VERSION ""

NS_ :

BS_:

BU_:

BO_ 2284109824 BMU_Heartbeat: 7 Vector__XXX
 SG_ BMU_Heartbeat_State : 0|8@1+ (1,0) [0|0] "" Vector__XXX
 SG_ BMU_Heartbeat_Flags : 8|32@1+ (1,0) [0|0] "" Vector__XXX

BO_ 2290139136 VCU_Heartbeat_SHDN: 6 Vector__XXX
 SG_ VCU_Heartbeat_SHDN_State : 0|8@1+ (1,0) [0|0] "" Vector__XXX
 SG_ VCU_Heartbeat_SHDN_Flags : 8|32@1+ (1,0) [0|0] "" Vector__XXX

BO_ 2290139137 VCU_Heartbeat_CTRL: 6 Vector__XXX
 SG_ VCU_Heartbeat_CTRL_State : 0|8@1+ (1,0) [0|0] "" Vector__XXX
 SG_ VCU_Heartbeat_CTRL_Flags : 8|32@1+ (1,0) [0|0] "" Vector__XXX

BO_ 2290139138 VCU_Heartbeat_DASH: 6 Vector__XXX
 SG_ VCU_Heartbeat_DASH_State : 0|8@1+ (1,0) [0|0] "" Vector__XXX
 SG_ VCU_Heartbeat_DASH_Flags : 8|32@1+ (1,0) [0|0] "" Vector__XXX

BO_ 2290139139 VCU_Heartbeat_EBS: 6 Vector__XXX
 SG_ VCU_Heartbeat_EBS_State : 0|8@1+ (1,0) [0|0] "" Vector__XXX
 SG_ VCU_Heartbeat_EBS_Flags : 8|32@1+ (1,0) [0|0] "" Vector__XXX

BO_ 2290139140 VCU_Heartbeat_ASSI: 6 Vector__XXX
 SG_ VCU_Heartbeat_ASSI_State : 0|8@1+ (1,0) [0|0] "" Vector__XXX
 SG_ VCU_Heartbeat_ASSI_Flags : 8|32@1+ (1,0) [0|0] "" Vector__XXX

BO_ 2290139141 VCU_Heartbeat_EBS_ADC: 6 Vector__XXX
 SG_ VCU_Heartbeat_EBS_ADC_State : 0|8@1+ (1,0) [0|0] "" Vector__XXX
 SG_ VCU_Heartbeat_EBS_ADC_Flags : 8|32@1+ (1,0) [0|0] "" Vector__XXX

BO_ 2290139142 VCU_Heartbeat_ACCU: 6 Vector__XXX
 SG_ VCU_Heartbeat_ACCU_State : 0|8@1+ (1,0) [0|0] "" Vector__XXX
 SG_ VCU_Heartbeat_ACCU_Flags : 8|32@1+ (1,0) [0|0] "" Vector__XXX

BO_ 2290139143 VCU_Heartbeat_COOL_L: 6 Vector__XXX
 SG_ VCU_Heartbeat_COOL_L_State : 0|8@1+ (1,0) [0|0] "" Vector__XXX
 SG_ VCU_Heartbeat_COOL_L_Flags : 8|32@1+ (1,0) [0|0] "" Vector__XXX

BO_ 2290139144 VCU_Heartbeat_COOL_R: 6 Vector__XXX
 SG_ VCU_Heartbeat_COOL_R_State : 0|8@1+ (1,0) [0|0] "" Vector__XXX
 SG_ VCU_Heartbeat_COOL_R_Flags : 8|32@1+ (1,0) [0|0] "" Vector__XXX

BO_ 2290139145 VCU_Heartbeat_SENSOR: 6 Vector__XXX
 SG_ VCU_Heartbeat_SENSOR_State : 0|8@1+ (1,0) [0|0] "" Vector__XXX
 SG_ VCU_Heartbeat_SENSOR_Flags : 8|32@1+ (1,0) [0|0] "" Vector__XXX

BO_ 2424340480 VCU_ShutdownStatus: 3 Vector__XXX
 SG_ VCU_ShutdownLines : 0|16@1+ (1,0) [0|0] "" Vector__XXX
 SG_ VCU_ShutdownStatus : 16|8@1+ (1,0) [0|1] "" Vector__XXX

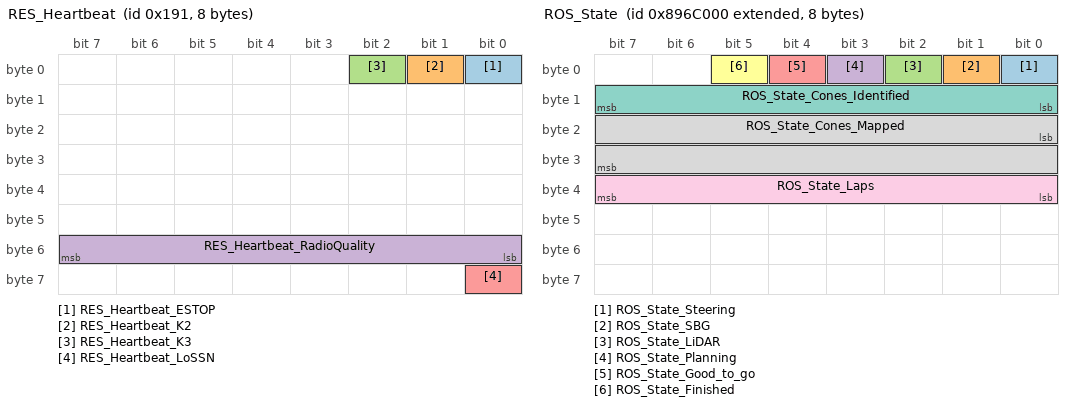
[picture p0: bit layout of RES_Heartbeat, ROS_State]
BO_ 401 RES_Heartbeat: 8 Vector__XXX
 SG_ RES_Heartbeat_ESTOP : 0|1@1- (1,0) [0|1] "" Vector__XXX
 SG_ RES_Heartbeat_K2 : 1|1@1- (1,0) [0|1] "" Vector__XXX
 SG_ RES_Heartbeat_K3 : 2|1@1- (1,0) [0|1] "" Vector__XXX
 SG_ RES_Heartbeat_RadioQuality : 48|8@1+ (1,0) [0|255] "" Vector__XXX
 SG_ RES_Heartbeat_LoSSN : 56|1@1- (1,0) [0|1] "" Vector__XXX

BO_ 2286731264 EBS_CTRL_Heartbeat: 8 Vector___XXX
 SG_ EBS_CTRL_Heartbeat_State : 0|8@1+ (1, 0) [0|0] "" Vector__XXX
 SG_ EBS_CTRL_Heartbeat_Flags : 8|32@1+ (1, 0) [0|0] "" Vector__XXX

BO_ 2286206977 MCISO_Heartbeat_Right: 8 Vector__XXX
 SG_ MCISO_Heartbeat_Right_State : 0|8@1+ (1,0) [0|0] "" Vector__XXX
 SG_ MCISO_Heartbeat_Right_Flags : 8|8@1+ (1,0) [0|0] "" Vector__XXX

BO_ 2286206976 MCISO_Heartbeat_Left: 8 Vector__XXX
 SG_ MCISO_Heartbeat_Left_State : 0|8@1+ (1,0) [0|0] "" Vector__XXX
 SG_ MCISO_Heartbeat_Left_Flags : 8|8@1+ (1,0) [0|0] "" Vector__XXX

BO_ 2290401280 SW_Heartbeat: 8 Vector__XXX
 SG_ SW_Heartbeat_State : 0|8@1+ (1,0) [0|0] "" Vector__XXX
 SG_ SW_Heartbeat_MissionID : 8|8@1+ (1,0) [0|0] "" Vector__XXX
 SG_ SW_Heartbeat_Flags : 16|16@1+ (1,0) [0|0] "" Vector__XXX

BO_ 2425274368 DVL_Heartbeat: 8 Vector__XXX
 SG_ DVL_Heartbeat_State : 0|8@1+ (1,0) [0|0] "" Vector__XXX
 SG_ DVL_Heartbeat_Flags : 8|32@1+ (1,0) [0|0] "" Vector__XXX

BO_ 2291318784 AV_State: 8 Vector__XXX
 SG_ AV_State_Mode : 0|8@1+ (1,0) [0|0] "" Vector__XXX
 SG_ AV_State_Mission : 8|8@1+ (1,0) [0|0] "" Vector__XXX
 SG_ AV_State_Status : 16|8@1+ (1,0) [0|0] "" Vector__XXX

BO_ 2291580928 ROS_State: 8 Vector__XXX
 SG_ ROS_State_Steering : 0|1@1+ (1,0) [0|0] "" Vector__XXX
 SG_ ROS_State_SBG : 1|1@1+ (1,0) [0|0] "" Vector__XXX
 SG_ ROS_State_LiDAR : 2|1@1+ (1,0) [0|0] "" Vector__XXX
 SG_ ROS_State_Planning : 3|1@1+ (1,0) [0|0] "" Vector__XXX
 SG_ ROS_State_Good_to_go : 4|1@1+ (1,0) [0|0] "" Vector__XXX
 SG_ ROS_State_Finished : 5|1@1+ (1,0) [0|0] "" Vector__XXX

 SG_ ROS_State_Cones_Identified : 8|8@1+ (1,0) [0|0] "" Vector__XXX
 SG_ ROS_State_Cones_Mapped : 16|16@1+ (1,0) [0|0] "" Vector__XXX
 SG_ ROS_State_Laps : 32|8@1+ (1,0) [0|0] "" Vector__XXX

BO_ 2424340665 VCU_Suspension_Rot_Front: 8 Vector__XXX
 SG_ VCU_Suspension_Rot_FL_ADC : 7|16@0+ (1,0) [0|0] "" Vector__XXX
 SG_ VCU_Suspension_Rot_FR_ADC : 23|16@0+ (1,0) [0|0] "" Vector__XXX
 SG_ VCU_Suspension_Rot_FL : 39|16@0- (0.001,0) [0|0] "" Vector__XXX
 SG_ VCU_Suspension_Rot_FR : 55|16@0- (0.001,0) [0|0] "" Vector__XXX

BO_ 2424340662 VCU_Suspension_Rot_Rear: 8 Vector__XXX
 SG_ VCU_Suspension_Rot_RL_ADC : 7|16@0+ (1,0) [0|0] "" Vector__XXX
 SG_ VCU_Suspension_Rot_RR_ADC : 23|16@0+ (1,0) [0|0] "" Vector__XXX
 SG_ VCU_Suspension_Rot_RL : 39|16@0- (0.001,0) [0|0] "" Vector__XXX
 SG_ VCU_Suspension_Rot_RR : 55|16@0- (0.001,0) [0|0] "" Vector__XXX

BO_ 2424340648 VCU_Temp_Gearbox_Right: 8 Vector__XXX
 SG_ VCU_Gearbox_Temp_Right_ADC : 7|16@0+ (1,0) [0|0] "" Vector__XXX
 SG_ VCU_Gearbox_Temp_Right_R : 23|16@0+ (1,0) [0|0] "" Vector__XXX
 SG_ VCU_Gearbox_Temp_Right_Temp : 39|16@0+ (0.1,0) [0|0] "" Vector__XXX

BO_ 2424340647 VCU_Temp_Gearbox_Left: 8 Vector__XXX
 SG_ VCU_Gearbox_Temp_Left_ADC : 7|16@0+ (1,0) [0|0] "" Vector__XXX
 SG_ VCU_Gearbox_Temp_Left_R : 23|16@0+ (1,0) [0|0] "" Vector__XXX
 SG_ VCU_Gearbox_Temp_Left_Temp : 39|16@0+ (0.1,0) [0|0] "" Vector__XXX

BO_ 2424340560 VCU_AirPressure: 8 Vector__XXX
 SG_ VCU_AirPressure_ADC : 7|16@0+ (1,0) [0|0] "" Vector__XXX

BO_ 2424340546 VCU_SuspensionTravel_DASH: 8 Vector__XXX
 SG_ VCU_SuspensionTravel_ADC_FL : 15|16@0+ (1,0) [0|0] "" Vector__XXX
 SG_ VCU_SuspensionTravel_ADC_FR : 31|16@0+ (1,0) [0|0] "" Vector__XXX

BO_ 2424340544 VCU_SuspensionTravel_SHDN: 8 Vector__XXX
 SG_ VCU_SuspensionTravel_ADC_RL : 15|16@0+ (1,0) [0|0] "" Vector__XXX
 SG_ VCU_SuspensionTravel_ADC_RR : 31|16@0+ (1,0) [0|0] "" Vector__XXX

BO_ 2424340512 VCU_Pedal_Accel: 8 Vector__XXX
 SG_ VCU_Pedal_Accel_0 : 7|16@0+ (1,0) [0|0] "" Vector__XXX
 SG_ VCU_Pedal_Accel_1 : 23|16@0+ (1,0) [0|0] "" Vector__XXX
 SG_ VCU_Pedal_Accel_ADC_0 : 39|16@0+ (1,0) [0|0] "" Vector__XXX
 SG_ VCU_Pedal_Accel_ADC_1 : 55|16@0+ (1,0) [0|0] "" Vector__XXX

BO_ 2424340528 VCU_Pedal_Brake: 8 Vector__XXX
 SG_ VCU_Pedal_Brake_ADC_0 : 7|16@0+ (1,0) [0|0] "" Vector__XXX
 SG_ VCU_Pedal_Brake_ADC_1 : 23|16@0+ (1,0) [0|0] "" Vector__XXX
 SG_ VCU_Pedal_Brake_PSI_0 : 39|16@0- (0.0625,0) [0|0] "" Vector__XXX
 SG_ VCU_Pedal_Brake_PSI_1 : 55|16@0- (0.0625,0) [0|0] "" Vector__XXX

BO_ 2424340576 VCU_TransmitSteering: 8 Vector__XXX
 SG_ VCU_Steering_0 : 0|16@1- (0.1,0) [0|0] "deg" Vector__XXX
 SG_ VCU_Steering_1 : 16|16@1- (0.1,0) [0|0] "deg" Vector__XXX
 SG_ VCU_Steering_ADC_0 : 32|16@1+ (0.1,0) [0|0] "" Vector__XXX
 SG_ VCU_Steering_ADC_1 : 48|16@1+ (0.1,0) [0|0] "" Vector__XXX

BO_ 2424340688 VCU_Wheel_Speed_Front: 8 Vector__XXX
 SG_ VCU_Wheel_Freq_FL : 7|16@0+ (1,0) [0|0] "" Vector__XXX
 SG_ VCU_Wheel_Freq_FR : 23|16@0+ (1,0) [0|0] "" Vector__XXX
 SG_ VCU_Wheel_RPM_FL : 39|16@0+ (0.1,0) [0|0] "" Vector__XXX
 SG_ VCU_Wheel_RPM_FR : 55|16@0+ (0.1,0) [0|0] "" Vector__XXX

BO_ 2418314752 BMU_TransmitPower: 8 Vector__XXX
 SG_ BMU_Power : 0|4@1- (0.001,0) [0|0] "" Vector__XXX

BO_ 2418314496 BMU_TransmitPackInfo: 8 Vector__XXX
 SG_ BMU_PackCurrent : 0|32@1- (1E-006,0) [0|0] "" Vector__XXX
 SG_ BMU_PackVoltage : 32|32@1- (1E-006,0) [0|0] "" Vector__XXX

BO_ 2418311168 BMU_TransmitVoltage_N_0_P_0: 8 Vector__XXX
 SG_ BMU_Voltage_C0_0 : 0|16@1+ (1,0) [0|0] "" Vector__XXX
 SG_ BMU_Voltage_C0_1 : 16|16@1+ (1,0) [0|0] "" Vector__XXX
 SG_ BMU_Voltage_C0_2 : 32|16@1+ (1,0) [0|0] "" Vector__XXX
 SG_ BMU_Voltage_Age_C0 : 48|16@1+ (1,0) [0|0] "" Vector__XXX

BO_ 2418311169 BMU_TransmitVoltage_N_0_P_1: 8 Vector__XXX
 SG_ BMU_Voltage_C0_3 : 0|16@1+ (1,0) [0|0] "" Vector__XXX
 SG_ BMU_Voltage_C0_4 : 16|16@1+ (1,0) [0|0] "" Vector__XXX
 SG_ BMU_Voltage_C0_5 : 32|16@1+ (1,0) [0|0] "" Vector__XXX
 SG_ BMU_Voltage_Age_C0 : 48|16@1+ (1,0) [0|0] "" Vector__XXX

BO_ 2418311170 BMU_TransmitVoltage_N_0_P_2: 8 Vector__XXX
 SG_ BMU_Voltage_C0_6 : 0|16@1+ (1,0) [0|0] "" Vector__XXX
 SG_ BMU_Voltage_C0_7 : 16|16@1+ (1,0) [0|0] "" Vector__XXX
 SG_ BMU_Voltage_C0_8 : 32|16@1+ (1,0) [0|0] "" Vector__XXX
 SG_ BMU_Voltage_Age_C0 : 48|16@1+ (1,0) [0|0] "" Vector__XXX

BO_ 2418311171 BMU_TransmitVoltage_N_0_P_3: 8 Vector__XXX
 SG_ BMU_Voltage_C0_9 : 0|16@1+ (1,0) [0|0] "" Vector__XXX
 SG_ BMU_Voltage_C0_10 : 16|16@1+ (1,0) [0|0] "" Vector__XXX
 SG_ BMU_Voltage_C0_11 : 32|16@1+ (1,0) [0|0] "" Vector__XXX
 SG_ BMU_Voltage_Age_C0 : 48|16@1+ (1,0) [0|0] "" Vector__XXX

BO_ 2418311172 BMU_TransmitVoltage_N_0_P_4: 8 Vector__XXX
 SG_ BMU_Voltage_C0_12 : 0|16@1+ (1,0) [0|0] "" Vector__XXX
 SG_ BMU_Voltage_C0_13 : 16|16@1+ (1,0) [0|0] "" Vector__XXX
 SG_ BMU_Voltage_Age_C0 : 48|16@1+ (1,0) [0|0] "" Vector__XXX

BO_ 2418311184 BMU_TransmitVoltage_N_1_P_0: 8 Vector__XXX
 SG_ BMU_Voltage_C1_0 : 0|16@1+ (1,0) [0|0] "" Vector__XXX
 SG_ BMU_Voltage_C1_1 : 16|16@1+ (1,0) [0|0] "" Vector__XXX
 SG_ BMU_Voltage_C1_2 : 32|16@1+ (1,0) [0|0] "" Vector__XXX
 SG_ BMU_Voltage_Age_C1 : 48|16@1+ (1,0) [0|0] "" Vector__XXX

BO_ 2418311185 BMU_TransmitVoltage_N_1_P_1: 8 Vector__XXX
 SG_ BMU_Voltage_C1_3 : 0|16@1+ (1,0) [0|0] "" Vector__XXX
 SG_ BMU_Voltage_C1_4 : 16|16@1+ (1,0) [0|0] "" Vector__XXX
 SG_ BMU_Voltage_C1_5 : 32|16@1+ (1,0) [0|0] "" Vector__XXX
 SG_ BMU_Voltage_Age_C1 : 48|16@1+ (1,0) [0|0] "" Vector__XXX

BO_ 2418311186 BMU_TransmitVoltage_N_1_P_2: 8 Vector__XXX
 SG_ BMU_Voltage_C1_6 : 0|16@1+ (1,0) [0|0] "" Vector__XXX
 SG_ BMU_Voltage_C1_7 : 16|16@1+ (1,0) [0|0] "" Vector__XXX
 SG_ BMU_Voltage_C1_8 : 32|16@1+ (1,0) [0|0] "" Vector__XXX
 SG_ BMU_Voltage_Age_C1 : 48|16@1+ (1,0) [0|0] "" Vector__XXX

BO_ 2418311187 BMU_TransmitVoltage_N_1_P_3: 8 Vector__XXX
 SG_ BMU_Voltage_C1_9 : 0|16@1+ (1,0) [0|0] "" Vector__XXX
 SG_ BMU_Voltage_C1_10 : 16|16@1+ (1,0) [0|0] "" Vector__XXX
 SG_ BMU_Voltage_C1_11 : 32|16@1+ (1,0) [0|0] "" Vector__XXX
 SG_ BMU_Voltage_Age_C1 : 48|16@1+ (1,0) [0|0] "" Vector__XXX

BO_ 2418311188 BMU_TransmitVoltage_N_1_P_4: 8 Vector__XXX
 SG_ BMU_Voltage_C1_12 : 0|16@1+ (1,0) [0|0] "" Vector__XXX
 SG_ BMU_Voltage_C1_13 : 16|16@1+ (1,0) [0|0] "" Vector__XXX
 SG_ BMU_Voltage_Age_C1 : 48|16@1+ (1,0) [0|0] "" Vector__XXX

BO_ 2418311200 BMU_TransmitVoltage_N_2_P_0: 8 Vector__XXX
 SG_ BMU_Voltage_C2_0 : 0|16@1+ (1,0) [0|0] "" Vector__XXX
 SG_ BMU_Voltage_C2_1 : 16|16@1+ (1,0) [0|0] "" Vector__XXX
 SG_ BMU_Voltage_C2_2 : 32|16@1+ (1,0) [0|0] "" Vector__XXX
 SG_ BMU_Voltage_Age_C2 : 48|16@1+ (1,0) [0|0] "" Vector__XXX

BO_ 2418311201 BMU_TransmitVoltage_N_2_P_1: 8 Vector__XXX
 SG_ BMU_Voltage_C2_3 : 0|16@1+ (1,0) [0|0] "" Vector__XXX
 SG_ BMU_Voltage_C2_4 : 16|16@1+ (1,0) [0|0] "" Vector__XXX
 SG_ BMU_Voltage_C2_5 : 32|16@1+ (1,0) [0|0] "" Vector__XXX
 SG_ BMU_Voltage_Age_C2 : 48|16@1+ (1,0) [0|0] "" Vector__XXX

BO_ 2418311202 BMU_TransmitVoltage_N_2_P_2: 8 Vector__XXX
 SG_ BMU_Voltage_C2_6 : 0|16@1+ (1,0) [0|0] "" Vector__XXX
 SG_ BMU_Voltage_C2_7 : 16|16@1+ (1,0) [0|0] "" Vector__XXX
 SG_ BMU_Voltage_C2_8 : 32|16@1+ (1,0) [0|0] "" Vector__XXX
 SG_ BMU_Voltage_Age_C2 : 48|16@1+ (1,0) [0|0] "" Vector__XXX

BO_ 2418311203 BMU_TransmitVoltage_N_2_P_3: 8 Vector__XXX
 SG_ BMU_Voltage_C2_9 : 0|16@1+ (1,0) [0|0] "" Vector__XXX
 SG_ BMU_Voltage_C2_10 : 16|16@1+ (1,0) [0|0] "" Vector__XXX
 SG_ BMU_Voltage_C2_11 : 32|16@1+ (1,0) [0|0] "" Vector__XXX
 SG_ BMU_Voltage_Age_C2 : 48|16@1+ (1,0) [0|0] "" Vector__XXX

BO_ 2418311204 BMU_TransmitVoltage_N_2_P_4: 8 Vector__XXX
 SG_ BMU_Voltage_C2_12 : 0|16@1+ (1,0) [0|0] "" Vector__XXX
 SG_ BMU_Voltage_C2_13 : 16|16@1+ (1,0) [0|0] "" Vector__XXX
 SG_ BMU_Voltage_Age_C2 : 48|16@1+ (1,0) [0|0] "" Vector__XXX

BO_ 2418311216 BMU_TransmitVoltage_N_3_P_0: 8 Vector__XXX
 SG_ BMU_Voltage_C3_0 : 0|16@1+ (1,0) [0|0] "" Vector__XXX
 SG_ BMU_Voltage_C3_1 : 16|16@1+ (1,0) [0|0] "" Vector__XXX
 SG_ BMU_Voltage_C3_2 : 32|16@1+ (1,0) [0|0] "" Vector__XXX
 SG_ BMU_Voltage_Age_C3 : 48|16@1+ (1,0) [0|0] "" Vector__XXX

BO_ 2418311217 BMU_TransmitVoltage_N_3_P_1: 8 Vector__XXX
 SG_ BMU_Voltage_C3_3 : 0|16@1+ (1,0) [0|0] "" Vector__XXX
 SG_ BMU_Voltage_C3_4 : 16|16@1+ (1,0) [0|0] "" Vector__XXX
 SG_ BMU_Voltage_C3_5 : 32|16@1+ (1,0) [0|0] "" Vector__XXX
 SG_ BMU_Voltage_Age_C3 : 48|16@1+ (1,0) [0|0] "" Vector__XXX

BO_ 2418311218 BMU_TransmitVoltage_N_3_P_2: 8 Vector__XXX
 SG_ BMU_Voltage_C3_6 : 0|16@1+ (1,0) [0|0] "" Vector__XXX
 SG_ BMU_Voltage_C3_7 : 16|16@1+ (1,0) [0|0] "" Vector__XXX
 SG_ BMU_Voltage_C3_8 : 32|16@1+ (1,0) [0|0] "" Vector__XXX
 SG_ BMU_Voltage_Age_C3 : 48|16@1+ (1,0) [0|0] "" Vector__XXX

BO_ 2418311219 BMU_TransmitVoltage_N_3_P_3: 8 Vector__XXX
 SG_ BMU_Voltage_C3_9 : 0|16@1+ (1,0) [0|0] "" Vector__XXX
 SG_ BMU_Voltage_C3_10 : 16|16@1+ (1,0) [0|0] "" Vector__XXX
 SG_ BMU_Voltage_C3_11 : 32|16@1+ (1,0) [0|0] "" Vector__XXX
 SG_ BMU_Voltage_Age_C3 : 48|16@1+ (1,0) [0|0] "" Vector__XXX

BO_ 2418311220 BMU_TransmitVoltage_N_3_P_4: 8 Vector__XXX
 SG_ BMU_Voltage_C3_12 : 0|16@1+ (1,0) [0|0] "" Vector__XXX
 SG_ BMU_Voltage_C3_13 : 16|16@1+ (1,0) [0|0] "" Vector__XXX
 SG_ BMU_Voltage_Age_C3 : 48|16@1+ (1,0) [0|0] "" Vector__XXX

BO_ 2418311232 BMU_TransmitVoltage_N_4_P_0: 8 Vector__XXX
 SG_ BMU_Voltage_C4_0 : 0|16@1+ (1,0) [0|0] "" Vector__XXX
 SG_ BMU_Voltage_C4_1 : 16|16@1+ (1,0) [0|0] "" Vector__XXX
 SG_ BMU_Voltage_C4_2 : 32|16@1+ (1,0) [0|0] "" Vector__XXX
 SG_ BMU_Voltage_Age_C4 : 48|16@1+ (1,0) [0|0] "" Vector__XXX

BO_ 2418311233 BMU_TransmitVoltage_N_4_P_1: 8 Vector__XXX
 SG_ BMU_Voltage_C4_3 : 0|16@1+ (1,0) [0|0] "" Vector__XXX
 SG_ BMU_Voltage_C4_4 : 16|16@1+ (1,0) [0|0] "" Vector__XXX
 SG_ BMU_Voltage_C4_5 : 32|16@1+ (1,0) [0|0] "" Vector__XXX
 SG_ BMU_Voltage_Age_C4 : 48|16@1+ (1,0) [0|0] "" Vector__XXX

BO_ 2418311234 BMU_TransmitVoltage_N_4_P_2: 8 Vector__XXX
 SG_ BMU_Voltage_C4_6 : 0|16@1+ (1,0) [0|0] "" Vector__XXX
 SG_ BMU_Voltage_C4_7 : 16|16@1+ (1,0) [0|0] "" Vector__XXX
 SG_ BMU_Voltage_C4_8 : 32|16@1+ (1,0) [0|0] "" Vector__XXX
 SG_ BMU_Voltage_Age_C4 : 48|16@1+ (1,0) [0|0] "" Vector__XXX

BO_ 2418311235 BMU_TransmitVoltage_N_4_P_3: 8 Vector__XXX
 SG_ BMU_Voltage_C4_9 : 0|16@1+ (1,0) [0|0] "" Vector__XXX
 SG_ BMU_Voltage_C4_10 : 16|16@1+ (1,0) [0|0] "" Vector__XXX
 SG_ BMU_Voltage_C4_11 : 32|16@1+ (1,0) [0|0] "" Vector__XXX
 SG_ BMU_Voltage_Age_C4 : 48|16@1+ (1,0) [0|0] "" Vector__XXX

BO_ 2418311236 BMU_TransmitVoltage_N_4_P_4: 8 Vector__XXX
 SG_ BMU_Voltage_C4_12 : 0|16@1+ (1,0) [0|0] "" Vector__XXX
 SG_ BMU_Voltage_C4_13 : 16|16@1+ (1,0) [0|0] "" Vector__XXX
 SG_ BMU_Voltage_Age_C4 : 48|16@1+ (1,0) [0|0] "" Vector__XXX

BO_ 2418311248 BMU_TransmitVoltage_N_5_P_0: 8 Vector__XXX
 SG_ BMU_Voltage_C5_0 : 0|16@1+ (1,0) [0|0] "" Vector__XXX
 SG_ BMU_Voltage_C5_1 : 16|16@1+ (1,0) [0|0] "" Vector__XXX
 SG_ BMU_Voltage_C5_2 : 32|16@1+ (1,0) [0|0] "" Vector__XXX
 SG_ BMU_Voltage_Age_C5 : 48|16@1+ (1,0) [0|0] "" Vector__XXX

BO_ 2418311249 BMU_TransmitVoltage_N_5_P_1: 8 Vector__XXX
 SG_ BMU_Voltage_C5_3 : 0|16@1+ (1,0) [0|0] "" Vector__XXX
 SG_ BMU_Voltage_C5_4 : 16|16@1+ (1,0) [0|0] "" Vector__XXX
 SG_ BMU_Voltage_C5_5 : 32|16@1+ (1,0) [0|0] "" Vector__XXX
 SG_ BMU_Voltage_Age_C5 : 48|16@1+ (1,0) [0|0] "" Vector__XXX

BO_ 2418311250 BMU_TransmitVoltage_N_5_P_2: 8 Vector__XXX
 SG_ BMU_Voltage_C5_6 : 0|16@1+ (1,0) [0|0] "" Vector__XXX
 SG_ BMU_Voltage_C5_7 : 16|16@1+ (1,0) [0|0] "" Vector__XXX
 SG_ BMU_Voltage_C5_8 : 32|16@1+ (1,0) [0|0] "" Vector__XXX
 SG_ BMU_Voltage_Age_C5 : 48|16@1+ (1,0) [0|0] "" Vector__XXX

BO_ 2418311251 BMU_TransmitVoltage_N_5_P_3: 8 Vector__XXX
 SG_ BMU_Voltage_C5_9 : 0|16@1+ (1,0) [0|0] "" Vector__XXX
 SG_ BMU_Voltage_C5_10 : 16|16@1+ (1,0) [0|0] "" Vector__XXX
 SG_ BMU_Voltage_C5_11 : 32|16@1+ (1,0) [0|0] "" Vector__XXX
 SG_ BMU_Voltage_Age_C5 : 48|16@1+ (1,0) [0|0] "" Vector__XXX

BO_ 2418311252 BMU_TransmitVoltage_N_5_P_4: 8 Vector__XXX
 SG_ BMU_Voltage_C5_12 : 0|16@1+ (1,0) [0|0] "" Vector__XXX
 SG_ BMU_Voltage_C5_13 : 16|16@1+ (1,0) [0|0] "" Vector__XXX
 SG_ BMU_Voltage_Age_C5 : 48|16@1+ (1,0) [0|0] "" Vector__XXX

BO_ 2418311264 BMU_TransmitVoltage_N_6_P_0: 8 Vector__XXX
 SG_ BMU_Voltage_C6_0 : 0|16@1+ (1,0) [0|0] "" Vector__XXX
 SG_ BMU_Voltage_C6_1 : 16|16@1+ (1,0) [0|0] "" Vector__XXX
 SG_ BMU_Voltage_C6_2 : 32|16@1+ (1,0) [0|0] "" Vector__XXX
 SG_ BMU_Voltage_Age_C6 : 48|16@1+ (1,0) [0|0] "" Vector__XXX

BO_ 2418311265 BMU_TransmitVoltage_N_6_P_1: 8 Vector__XXX
 SG_ BMU_Voltage_C6_3 : 0|16@1+ (1,0) [0|0] "" Vector__XXX
 SG_ BMU_Voltage_C6_4 : 16|16@1+ (1,0) [0|0] "" Vector__XXX
 SG_ BMU_Voltage_C6_5 : 32|16@1+ (1,0) [0|0] "" Vector__XXX
 SG_ BMU_Voltage_Age_C6 : 48|16@1+ (1,0) [0|0] "" Vector__XXX

BO_ 2418311266 BMU_TransmitVoltage_N_6_P_2: 8 Vector__XXX
 SG_ BMU_Voltage_C6_6 : 0|16@1+ (1,0) [0|0] "" Vector__XXX
 SG_ BMU_Voltage_C6_7 : 16|16@1+ (1,0) [0|0] "" Vector__XXX
 SG_ BMU_Voltage_C6_8 : 32|16@1+ (1,0) [0|0] "" Vector__XXX
 SG_ BMU_Voltage_Age_C6 : 48|16@1+ (1,0) [0|0] "" Vector__XXX

BO_ 2418311267 BMU_TransmitVoltage_N_6_P_3: 8 Vector__XXX
 SG_ BMU_Voltage_C6_9 : 0|16@1+ (1,0) [0|0] "" Vector__XXX
 SG_ BMU_Voltage_C6_10 : 16|16@1+ (1,0) [0|0] "" Vector__XXX
 SG_ BMU_Voltage_C6_11 : 32|16@1+ (1,0) [0|0] "" Vector__XXX
 SG_ BMU_Voltage_Age_C6 : 48|16@1+ (1,0) [0|0] "" Vector__XXX

BO_ 2418311268 BMU_TransmitVoltage_N_6_P_4: 8 Vector__XXX
 SG_ BMU_Voltage_C6_12 : 0|16@1+ (1,0) [0|0] "" Vector__XXX
 SG_ BMU_Voltage_C6_13 : 16|16@1+ (1,0) [0|0] "" Vector__XXX
 SG_ BMU_Voltage_Age_C6 : 48|16@1+ (1,0) [0|0] "" Vector__XXX

BO_ 2418311280 BMU_TransmitVoltage_N_7_P_0: 8 Vector__XXX
 SG_ BMU_Voltage_C7_0 : 0|16@1+ (1,0) [0|0] "" Vector__XXX
 SG_ BMU_Voltage_C7_1 : 16|16@1+ (1,0) [0|0] "" Vector__XXX
 SG_ BMU_Voltage_C7_2 : 32|16@1+ (1,0) [0|0] "" Vector__XXX
 SG_ BMU_Voltage_Age_C7 : 48|16@1+ (1,0) [0|0] "" Vector__XXX

BO_ 2418311281 BMU_TransmitVoltage_N_7_P_1: 8 Vector__XXX
 SG_ BMU_Voltage_C7_3 : 0|16@1+ (1,0) [0|0] "" Vector__XXX
 SG_ BMU_Voltage_C7_4 : 16|16@1+ (1,0) [0|0] "" Vector__XXX
 SG_ BMU_Voltage_C7_5 : 32|16@1+ (1,0) [0|0] "" Vector__XXX
 SG_ BMU_Voltage_Age_C7 : 48|16@1+ (1,0) [0|0] "" Vector__XXX

BO_ 2418311282 BMU_TransmitVoltage_N_7_P_2: 8 Vector__XXX
 SG_ BMU_Voltage_C7_6 : 0|16@1+ (1,0) [0|0] "" Vector__XXX
 SG_ BMU_Voltage_C7_7 : 16|16@1+ (1,0) [0|0] "" Vector__XXX
 SG_ BMU_Voltage_C7_8 : 32|16@1+ (1,0) [0|0] "" Vector__XXX
 SG_ BMU_Voltage_Age_C7 : 48|16@1+ (1,0) [0|0] "" Vector__XXX

BO_ 2418311283 BMU_TransmitVoltage_N_7_P_3: 8 Vector__XXX
 SG_ BMU_Voltage_C7_9 : 0|16@1+ (1,0) [0|0] "" Vector__XXX
 SG_ BMU_Voltage_C7_10 : 16|16@1+ (1,0) [0|0] "" Vector__XXX
 SG_ BMU_Voltage_C7_11 : 32|16@1+ (1,0) [0|0] "" Vector__XXX
 SG_ BMU_Voltage_Age_C7 : 48|16@1+ (1,0) [0|0] "" Vector__XXX

BO_ 2418311284 BMU_TransmitVoltage_N_7_P_4: 8 Vector__XXX
 SG_ BMU_Voltage_C7_12 : 0|16@1+ (1,0) [0|0] "" Vector__XXX
 SG_ BMU_Voltage_C7_13 : 16|16@1+ (1,0) [0|0] "" Vector__XXX
 SG_ BMU_Voltage_Age_C7 : 48|16@1+ (1,0) [0|0] "" Vector__XXX

BO_ 2418311296 BMU_TransmitVoltage_N_8_P_0: 8 Vector__XXX
 SG_ BMU_Voltage_C8_0 : 0|16@1+ (1,0) [0|0] "" Vector__XXX
 SG_ BMU_Voltage_C8_1 : 16|16@1+ (1,0) [0|0] "" Vector__XXX
 SG_ BMU_Voltage_C8_2 : 32|16@1+ (1,0) [0|0] "" Vector__XXX
 SG_ BMU_Voltage_Age_C8 : 48|16@1+ (1,0) [0|0] "" Vector__XXX

BO_ 2418311297 BMU_TransmitVoltage_N_8_P_1: 8 Vector__XXX
 SG_ BMU_Voltage_C8_3 : 0|16@1+ (1,0) [0|0] "" Vector__XXX
 SG_ BMU_Voltage_C8_4 : 16|16@1+ (1,0) [0|0] "" Vector__XXX
 SG_ BMU_Voltage_C8_5 : 32|16@1+ (1,0) [0|0] "" Vector__XXX
 SG_ BMU_Voltage_Age_C8 : 48|16@1+ (1,0) [0|0] "" Vector__XXX

BO_ 2418311298 BMU_TransmitVoltage_N_8_P_2: 8 Vector__XXX
 SG_ BMU_Voltage_C8_6 : 0|16@1+ (1,0) [0|0] "" Vector__XXX
 SG_ BMU_Voltage_C8_7 : 16|16@1+ (1,0) [0|0] "" Vector__XXX
 SG_ BMU_Voltage_C8_8 : 32|16@1+ (1,0) [0|0] "" Vector__XXX
 SG_ BMU_Voltage_Age_C8 : 48|16@1+ (1,0) [0|0] "" Vector__XXX

BO_ 2418311299 BMU_TransmitVoltage_N_8_P_3: 8 Vector__XXX
 SG_ BMU_Voltage_C8_9 : 0|16@1+ (1,0) [0|0] "" Vector__XXX
 SG_ BMU_Voltage_C8_10 : 16|16@1+ (1,0) [0|0] "" Vector__XXX
 SG_ BMU_Voltage_C8_11 : 32|16@1+ (1,0) [0|0] "" Vector__XXX
 SG_ BMU_Voltage_Age_C8 : 48|16@1+ (1,0) [0|0] "" Vector__XXX

BO_ 2418311300 BMU_TransmitVoltage_N_8_P_4: 8 Vector__XXX
 SG_ BMU_Voltage_C8_12 : 0|16@1+ (1,0) [0|0] "" Vector__XXX
 SG_ BMU_Voltage_C8_13 : 16|16@1+ (1,0) [0|0] "" Vector__XXX
 SG_ BMU_Voltage_Age_C8 : 48|16@1+ (1,0) [0|0] "" Vector__XXX

BO_ 2418311312 BMU_TransmitVoltage_N_9_P_0: 8 Vector__XXX
 SG_ BMU_Voltage_C9_0 : 0|16@1+ (1,0) [0|0] "" Vector__XXX
 SG_ BMU_Voltage_C9_1 : 16|16@1+ (1,0) [0|0] "" Vector__XXX
 SG_ BMU_Voltage_C9_2 : 32|16@1+ (1,0) [0|0] "" Vector__XXX
 SG_ BMU_Voltage_Age_C9 : 48|16@1+ (1,0) [0|0] "" Vector__XXX

BO_ 2418311313 BMU_TransmitVoltage_N_9_P_1: 8 Vector__XXX
 SG_ BMU_Voltage_C9_3 : 0|16@1+ (1,0) [0|0] "" Vector__XXX
 SG_ BMU_Voltage_C9_4 : 16|16@1+ (1,0) [0|0] "" Vector__XXX
 SG_ BMU_Voltage_C9_5 : 32|16@1+ (1,0) [0|0] "" Vector__XXX
 SG_ BMU_Voltage_Age_C9 : 48|16@1+ (1,0) [0|0] "" Vector__XXX

BO_ 2418311314 BMU_TransmitVoltage_N_9_P_2: 8 Vector__XXX
 SG_ BMU_Voltage_C9_6 : 0|16@1+ (1,0) [0|0] "" Vector__XXX
 SG_ BMU_Voltage_C9_7 : 16|16@1+ (1,0) [0|0] "" Vector__XXX
 SG_ BMU_Voltage_C9_8 : 32|16@1+ (1,0) [0|0] "" Vector__XXX
 SG_ BMU_Voltage_Age_C9 : 48|16@1+ (1,0) [0|0] "" Vector__XXX

BO_ 2418311315 BMU_TransmitVoltage_N_9_P_3: 8 Vector__XXX
 SG_ BMU_Voltage_C9_9 : 0|16@1+ (1,0) [0|0] "" Vector__XXX
 SG_ BMU_Voltage_C9_10 : 16|16@1+ (1,0) [0|0] "" Vector__XXX
 SG_ BMU_Voltage_C9_11 : 32|16@1+ (1,0) [0|0] "" Vector__XXX
 SG_ BMU_Voltage_Age_C9 : 48|16@1+ (1,0) [0|0] "" Vector__XXX

BO_ 2418311316 BMU_TransmitVoltage_N_9_P_4: 8 Vector__XXX
 SG_ BMU_Voltage_C9_12 : 0|16@1+ (1,0) [0|0] "" Vector__XXX
 SG_ BMU_Voltage_C9_13 : 16|16@1+ (1,0) [0|0] "" Vector__XXX
 SG_ BMU_Voltage_Age_C9 : 48|16@1+ (1,0) [0|0] "" Vector__XXX

BO_ 2418311328 BMU_TransmitVoltage_N_10_P_0: 8 Vector__XXX
 SG_ BMU_Voltage_C10_0 : 0|16@1+ (1,0) [0|0] "" Vector__XXX
 SG_ BMU_Voltage_C10_1 : 16|16@1+ (1,0) [0|0] "" Vector__XXX
 SG_ BMU_Voltage_C10_2 : 32|16@1+ (1,0) [0|0] "" Vector__XXX
 SG_ BMU_Voltage_Age_C10 : 48|16@1+ (1,0) [0|0] "" Vector__XXX

BO_ 2418311329 BMU_TransmitVoltage_N_10_P_1: 8 Vector__XXX
 SG_ BMU_Voltage_C10_3 : 0|16@1+ (1,0) [0|0] "" Vector__XXX
 SG_ BMU_Voltage_C10_4 : 16|16@1+ (1,0) [0|0] "" Vector__XXX
 SG_ BMU_Voltage_C10_5 : 32|16@1+ (1,0) [0|0] "" Vector__XXX
 SG_ BMU_Voltage_Age_C10 : 48|16@1+ (1,0) [0|0] "" Vector__XXX

BO_ 2418311330 BMU_TransmitVoltage_N_10_P_2: 8 Vector__XXX
 SG_ BMU_Voltage_C10_6 : 0|16@1+ (1,0) [0|0] "" Vector__XXX
 SG_ BMU_Voltage_C10_7 : 16|16@1+ (1,0) [0|0] "" Vector__XXX
 SG_ BMU_Voltage_C10_8 : 32|16@1+ (1,0) [0|0] "" Vector__XXX
 SG_ BMU_Voltage_Age_C10 : 48|16@1+ (1,0) [0|0] "" Vector__XXX

BO_ 2418311331 BMU_TransmitVoltage_N_10_P_3: 8 Vector__XXX
 SG_ BMU_Voltage_C10_9 : 0|16@1+ (1,0) [0|0] "" Vector__XXX
 SG_ BMU_Voltage_C10_10 : 16|16@1+ (1,0) [0|0] "" Vector__XXX
 SG_ BMU_Voltage_C10_11 : 32|16@1+ (1,0) [0|0] "" Vector__XXX
 SG_ BMU_Voltage_Age_C10 : 48|16@1+ (1,0) [0|0] "" Vector__XXX

BO_ 2418311332 BMU_TransmitVoltage_N_10_P_4: 8 Vector__XXX
 SG_ BMU_Voltage_C10_12 : 0|16@1+ (1,0) [0|0] "" Vector__XXX
 SG_ BMU_Voltage_C10_13 : 16|16@1+ (1,0) [0|0] "" Vector__XXX
 SG_ BMU_Voltage_Age_C10 : 48|16@1+ (1,0) [0|0] "" Vector__XXX

BO_ 2418311344 BMU_TransmitVoltage_N_11_P_0: 8 Vector__XXX
 SG_ BMU_Voltage_C11_0 : 0|16@1+ (1,0) [0|0] "" Vector__XXX
 SG_ BMU_Voltage_C11_1 : 16|16@1+ (1,0) [0|0] "" Vector__XXX
 SG_ BMU_Voltage_C11_2 : 32|16@1+ (1,0) [0|0] "" Vector__XXX
 SG_ BMU_Voltage_Age_C11 : 48|16@1+ (1,0) [0|0] "" Vector__XXX

BO_ 2418311345 BMU_TransmitVoltage_N_11_P_1: 8 Vector__XXX
 SG_ BMU_Voltage_C11_3 : 0|16@1+ (1,0) [0|0] "" Vector__XXX
 SG_ BMU_Voltage_C11_4 : 16|16@1+ (1,0) [0|0] "" Vector__XXX
 SG_ BMU_Voltage_C11_5 : 32|16@1+ (1,0) [0|0] "" Vector__XXX
 SG_ BMU_Voltage_Age_C11 : 48|16@1+ (1,0) [0|0] "" Vector__XXX

BO_ 2418311346 BMU_TransmitVoltage_N_11_P_2: 8 Vector__XXX
 SG_ BMU_Voltage_C11_6 : 0|16@1+ (1,0) [0|0] "" Vector__XXX
 SG_ BMU_Voltage_C11_7 : 16|16@1+ (1,0) [0|0] "" Vector__XXX
 SG_ BMU_Voltage_C11_8 : 32|16@1+ (1,0) [0|0] "" Vector__XXX
 SG_ BMU_Voltage_Age_C11 : 48|16@1+ (1,0) [0|0] "" Vector__XXX

BO_ 2418311347 BMU_TransmitVoltage_N_11_P_3: 8 Vector__XXX
 SG_ BMU_Voltage_C11_9 : 0|16@1+ (1,0) [0|0] "" Vector__XXX
 SG_ BMU_Voltage_C11_10 : 16|16@1+ (1,0) [0|0] "" Vector__XXX
 SG_ BMU_Voltage_C11_11 : 32|16@1+ (1,0) [0|0] "" Vector__XXX
 SG_ BMU_Voltage_Age_C11 : 48|16@1+ (1,0) [0|0] "" Vector__XXX

BO_ 2418311348 BMU_TransmitVoltage_N_11_P_4: 8 Vector__XXX
 SG_ BMU_Voltage_C11_12 : 0|16@1+ (1,0) [0|0] "" Vector__XXX
 SG_ BMU_Voltage_C11_13 : 16|16@1+ (1,0) [0|0] "" Vector__XXX
 SG_ BMU_Voltage_Age_C11 : 48|16@1+ (1,0) [0|0] "" Vector__XXX

BO_ 2418311360 BMU_TransmitVoltage_N_12_P_0: 8 Vector__XXX
 SG_ BMU_Voltage_C12_0 : 0|16@1+ (1,0) [0|0] "" Vector__XXX
 SG_ BMU_Voltage_C12_1 : 16|16@1+ (1,0) [0|0] "" Vector__XXX
 SG_ BMU_Voltage_C12_2 : 32|16@1+ (1,0) [0|0] "" Vector__XXX
 SG_ BMU_Voltage_Age_C12 : 48|16@1+ (1,0) [0|0] "" Vector__XXX

BO_ 2418311361 BMU_TransmitVoltage_N_12_P_1: 8 Vector__XXX
 SG_ BMU_Voltage_C12_3 : 0|16@1+ (1,0) [0|0] "" Vector__XXX
 SG_ BMU_Voltage_C12_4 : 16|16@1+ (1,0) [0|0] "" Vector__XXX
 SG_ BMU_Voltage_C12_5 : 32|16@1+ (1,0) [0|0] "" Vector__XXX
 SG_ BMU_Voltage_Age_C12 : 48|16@1+ (1,0) [0|0] "" Vector__XXX

BO_ 2418311362 BMU_TransmitVoltage_N_12_P_2: 8 Vector__XXX
 SG_ BMU_Voltage_C12_6 : 0|16@1+ (1,0) [0|0] "" Vector__XXX
 SG_ BMU_Voltage_C12_7 : 16|16@1+ (1,0) [0|0] "" Vector__XXX
 SG_ BMU_Voltage_C12_8 : 32|16@1+ (1,0) [0|0] "" Vector__XXX
 SG_ BMU_Voltage_Age_C12 : 48|16@1+ (1,0) [0|0] "" Vector__XXX

BO_ 2418311363 BMU_TransmitVoltage_N_12_P_3: 8 Vector__XXX
 SG_ BMU_Voltage_C12_9 : 0|16@1+ (1,0) [0|0] "" Vector__XXX
 SG_ BMU_Voltage_C12_10 : 16|16@1+ (1,0) [0|0] "" Vector__XXX
 SG_ BMU_Voltage_C12_11 : 32|16@1+ (1,0) [0|0] "" Vector__XXX
 SG_ BMU_Voltage_Age_C12 : 48|16@1+ (1,0) [0|0] "" Vector__XXX

BO_ 2418311364 BMU_TransmitVoltage_N_12_P_4: 8 Vector__XXX
 SG_ BMU_Voltage_C12_12 : 0|16@1+ (1,0) [0|0] "" Vector__XXX
 SG_ BMU_Voltage_C12_13 : 16|16@1+ (1,0) [0|0] "" Vector__XXX
 SG_ BMU_Voltage_Age_C12 : 48|16@1+ (1,0) [0|0] "" Vector__XXX

BO_ 2418311376 BMU_TransmitVoltage_N_13_P_0: 8 Vector__XXX
 SG_ BMU_Voltage_C13_0 : 0|16@1+ (1,0) [0|0] "" Vector__XXX
 SG_ BMU_Voltage_C13_1 : 16|16@1+ (1,0) [0|0] "" Vector__XXX
 SG_ BMU_Voltage_C13_2 : 32|16@1+ (1,0) [0|0] "" Vector__XXX
 SG_ BMU_Voltage_Age_C13 : 48|16@1+ (1,0) [0|0] "" Vector__XXX

BO_ 2418311377 BMU_TransmitVoltage_N_13_P_1: 8 Vector__XXX
 SG_ BMU_Voltage_C13_3 : 0|16@1+ (1,0) [0|0] "" Vector__XXX
 SG_ BMU_Voltage_C13_4 : 16|16@1+ (1,0) [0|0] "" Vector__XXX
 SG_ BMU_Voltage_C13_5 : 32|16@1+ (1,0) [0|0] "" Vector__XXX
 SG_ BMU_Voltage_Age_C13 : 48|16@1+ (1,0) [0|0] "" Vector__XXX

BO_ 2418311378 BMU_TransmitVoltage_N_13_P_2: 8 Vector__XXX
 SG_ BMU_Voltage_C13_6 : 0|16@1+ (1,0) [0|0] "" Vector__XXX
 SG_ BMU_Voltage_C13_7 : 16|16@1+ (1,0) [0|0] "" Vector__XXX
 SG_ BMU_Voltage_C13_8 : 32|16@1+ (1,0) [0|0] "" Vector__XXX
 SG_ BMU_Voltage_Age_C13 : 48|16@1+ (1,0) [0|0] "" Vector__XXX

BO_ 2418311379 BMU_TransmitVoltage_N_13_P_3: 8 Vector__XXX
 SG_ BMU_Voltage_C13_9 : 0|16@1+ (1,0) [0|0] "" Vector__XXX
 SG_ BMU_Voltage_C13_10 : 16|16@1+ (1,0) [0|0] "" Vector__XXX
 SG_ BMU_Voltage_C13_11 : 32|16@1+ (1,0) [0|0] "" Vector__XXX
 SG_ BMU_Voltage_Age_C13 : 48|16@1+ (1,0) [0|0] "" Vector__XXX

BO_ 2418311380 BMU_TransmitVoltage_N_13_P_4: 8 Vector__XXX
 SG_ BMU_Voltage_C13_12 : 0|16@1+ (1,0) [0|0] "" Vector__XXX
 SG_ BMU_Voltage_C13_13 : 16|16@1+ (1,0) [0|0] "" Vector__XXX
 SG_ BMU_Voltage_Age_C13 : 48|16@1+ (1,0) [0|0] "" Vector__XXX

BO_ 2418311392 BMU_TransmitVoltage_N_14_P_0: 8 Vector__XXX
 SG_ BMU_Voltage_C14_0 : 0|16@1+ (1,0) [0|0] "" Vector__XXX
 SG_ BMU_Voltage_C14_1 : 16|16@1+ (1,0) [0|0] "" Vector__XXX
 SG_ BMU_Voltage_C14_2 : 32|16@1+ (1,0) [0|0] "" Vector__XXX
 SG_ BMU_Voltage_Age_C14 : 48|16@1+ (1,0) [0|0] "" Vector__XXX

BO_ 2418311393 BMU_TransmitVoltage_N_14_P_1: 8 Vector__XXX
 SG_ BMU_Voltage_C14_3 : 0|16@1+ (1,0) [0|0] "" Vector__XXX
 SG_ BMU_Voltage_C14_4 : 16|16@1+ (1,0) [0|0] "" Vector__XXX
 SG_ BMU_Voltage_C14_5 : 32|16@1+ (1,0) [0|0] "" Vector__XXX
 SG_ BMU_Voltage_Age_C14 : 48|16@1+ (1,0) [0|0] "" Vector__XXX

BO_ 2418311394 BMU_TransmitVoltage_N_14_P_2: 8 Vector__XXX
 SG_ BMU_Voltage_C14_6 : 0|16@1+ (1,0) [0|0] "" Vector__XXX
 SG_ BMU_Voltage_C14_7 : 16|16@1+ (1,0) [0|0] "" Vector__XXX
 SG_ BMU_Voltage_C14_8 : 32|16@1+ (1,0) [0|0] "" Vector__XXX
 SG_ BMU_Voltage_Age_C14 : 48|16@1+ (1,0) [0|0] "" Vector__XXX

BO_ 2418311395 BMU_TransmitVoltage_N_14_P_3: 8 Vector__XXX
 SG_ BMU_Voltage_C14_9 : 0|16@1+ (1,0) [0|0] "" Vector__XXX
 SG_ BMU_Voltage_C14_10 : 16|16@1+ (1,0) [0|0] "" Vector__XXX
 SG_ BMU_Voltage_C14_11 : 32|16@1+ (1,0) [0|0] "" Vector__XXX
 SG_ BMU_Voltage_Age_C14 : 48|16@1+ (1,0) [0|0] "" Vector__XXX

BO_ 2418311396 BMU_TransmitVoltage_N_14_P_4: 8 Vector__XXX
 SG_ BMU_Voltage_C14_12 : 0|16@1+ (1,0) [0|0] "" Vector__XXX
 SG_ BMU_Voltage_C14_13 : 16|16@1+ (1,0) [0|0] "" Vector__XXX
 SG_ BMU_Voltage_Age_C14 : 48|16@1+ (1,0) [0|0] "" Vector__XXX

BO_ 2418311408 BMU_TransmitVoltage_N_15_P_0: 8 Vector__XXX
 SG_ BMU_Voltage_C15_0 : 0|16@1+ (1,0) [0|0] "" Vector__XXX
 SG_ BMU_Voltage_C15_1 : 16|16@1+ (1,0) [0|0] "" Vector__XXX
 SG_ BMU_Voltage_C15_2 : 32|16@1+ (1,0) [0|0] "" Vector__XXX
 SG_ BMU_Voltage_Age_C15 : 48|16@1+ (1,0) [0|0] "" Vector__XXX

BO_ 2418311409 BMU_TransmitVoltage_N_15_P_1: 8 Vector__XXX
 SG_ BMU_Voltage_C15_3 : 0|16@1+ (1,0) [0|0] "" Vector__XXX
 SG_ BMU_Voltage_C15_4 : 16|16@1+ (1,0) [0|0] "" Vector__XXX
 SG_ BMU_Voltage_C15_5 : 32|16@1+ (1,0) [0|0] "" Vector__XXX
 SG_ BMU_Voltage_Age_C15 : 48|16@1+ (1,0) [0|0] "" Vector__XXX

BO_ 2418311410 BMU_TransmitVoltage_N_15_P_2: 8 Vector__XXX
 SG_ BMU_Voltage_C15_6 : 0|16@1+ (1,0) [0|0] "" Vector__XXX
 SG_ BMU_Voltage_C15_7 : 16|16@1+ (1,0) [0|0] "" Vector__XXX
 SG_ BMU_Voltage_C15_8 : 32|16@1+ (1,0) [0|0] "" Vector__XXX
 SG_ BMU_Voltage_Age_C15 : 48|16@1+ (1,0) [0|0] "" Vector__XXX

BO_ 2418311411 BMU_TransmitVoltage_N_15_P_3: 8 Vector__XXX
 SG_ BMU_Voltage_C15_9 : 0|16@1+ (1,0) [0|0] "" Vector__XXX
 SG_ BMU_Voltage_C15_10 : 16|16@1+ (1,0) [0|0] "" Vector__XXX
 SG_ BMU_Voltage_C15_11 : 32|16@1+ (1,0) [0|0] "" Vector__XXX
 SG_ BMU_Voltage_Age_C15 : 48|16@1+ (1,0) [0|0] "" Vector__XXX

BO_ 2418311412 BMU_TransmitVoltage_N_15_P_4: 8 Vector__XXX
 SG_ BMU_Voltage_C15_12 : 0|16@1+ (1,0) [0|0] "" Vector__XXX
 SG_ BMU_Voltage_C15_13 : 16|16@1+ (1,0) [0|0] "" Vector__XXX
 SG_ BMU_Voltage_Age_C15 : 48|16@1+ (1,0) [0|0] "" Vector__XXX

BO_ 2418311424 BMU_TransmitVoltage_N_16_P_0: 8 Vector__XXX
 SG_ BMU_Voltage_C16_0 : 0|16@1+ (1,0) [0|0] "" Vector__XXX
 SG_ BMU_Voltage_C16_1 : 16|16@1+ (1,0) [0|0] "" Vector__XXX
 SG_ BMU_Voltage_C16_2 : 32|16@1+ (1,0) [0|0] "" Vector__XXX
 SG_ BMU_Voltage_Age_C16 : 48|16@1+ (1,0) [0|0] "" Vector__XXX

BO_ 2418311425 BMU_TransmitVoltage_N_16_P_1: 8 Vector__XXX
 SG_ BMU_Voltage_C16_3 : 0|16@1+ (1,0) [0|0] "" Vector__XXX
 SG_ BMU_Voltage_C16_4 : 16|16@1+ (1,0) [0|0] "" Vector__XXX
 SG_ BMU_Voltage_C16_5 : 32|16@1+ (1,0) [0|0] "" Vector__XXX
 SG_ BMU_Voltage_Age_C16 : 48|16@1+ (1,0) [0|0] "" Vector__XXX

BO_ 2418311426 BMU_TransmitVoltage_N_16_P_2: 8 Vector__XXX
 SG_ BMU_Voltage_C16_6 : 0|16@1+ (1,0) [0|0] "" Vector__XXX
 SG_ BMU_Voltage_C16_7 : 16|16@1+ (1,0) [0|0] "" Vector__XXX
 SG_ BMU_Voltage_C16_8 : 32|16@1+ (1,0) [0|0] "" Vector__XXX
 SG_ BMU_Voltage_Age_C16 : 48|16@1+ (1,0) [0|0] "" Vector__XXX

BO_ 2418311427 BMU_TransmitVoltage_N_16_P_3: 8 Vector__XXX
 SG_ BMU_Voltage_C16_9 : 0|16@1+ (1,0) [0|0] "" Vector__XXX
 SG_ BMU_Voltage_C16_10 : 16|16@1+ (1,0) [0|0] "" Vector__XXX
 SG_ BMU_Voltage_C16_11 : 32|16@1+ (1,0) [0|0] "" Vector__XXX
 SG_ BMU_Voltage_Age_C16 : 48|16@1+ (1,0) [0|0] "" Vector__XXX

BO_ 2418311428 BMU_TransmitVoltage_N_16_P_4: 8 Vector__XXX
 SG_ BMU_Voltage_C16_12 : 0|16@1+ (1,0) [0|0] "" Vector__XXX
 SG_ BMU_Voltage_C16_13 : 16|16@1+ (1,0) [0|0] "" Vector__XXX
 SG_ BMU_Voltage_Age_C16 : 48|16@1+ (1,0) [0|0] "" Vector__XXX

BO_ 2418311440 BMU_TransmitVoltage_N_17_P_0: 8 Vector__XXX
 SG_ BMU_Voltage_C17_0 : 0|16@1+ (1,0) [0|0] "" Vector__XXX
 SG_ BMU_Voltage_C17_1 : 16|16@1+ (1,0) [0|0] "" Vector__XXX
 SG_ BMU_Voltage_C17_2 : 32|16@1+ (1,0) [0|0] "" Vector__XXX
 SG_ BMU_Voltage_Age_C17 : 48|16@1+ (1,0) [0|0] "" Vector__XXX

BO_ 2418311441 BMU_TransmitVoltage_N_17_P_1: 8 Vector__XXX
 SG_ BMU_Voltage_C17_3 : 0|16@1+ (1,0) [0|0] "" Vector__XXX
 SG_ BMU_Voltage_C17_4 : 16|16@1+ (1,0) [0|0] "" Vector__XXX
 SG_ BMU_Voltage_C17_5 : 32|16@1+ (1,0) [0|0] "" Vector__XXX
 SG_ BMU_Voltage_Age_C17 : 48|16@1+ (1,0) [0|0] "" Vector__XXX

BO_ 2418311442 BMU_TransmitVoltage_N_17_P_2: 8 Vector__XXX
 SG_ BMU_Voltage_C17_6 : 0|16@1+ (1,0) [0|0] "" Vector__XXX
 SG_ BMU_Voltage_C17_7 : 16|16@1+ (1,0) [0|0] "" Vector__XXX
 SG_ BMU_Voltage_C17_8 : 32|16@1+ (1,0) [0|0] "" Vector__XXX
 SG_ BMU_Voltage_Age_C17 : 48|16@1+ (1,0) [0|0] "" Vector__XXX

BO_ 2418311443 BMU_TransmitVoltage_N_17_P_3: 8 Vector__XXX
 SG_ BMU_Voltage_C17_9 : 0|16@1+ (1,0) [0|0] "" Vector__XXX
 SG_ BMU_Voltage_C17_10 : 16|16@1+ (1,0) [0|0] "" Vector__XXX
 SG_ BMU_Voltage_C17_11 : 32|16@1+ (1,0) [0|0] "" Vector__XXX
 SG_ BMU_Voltage_Age_C17 : 48|16@1+ (1,0) [0|0] "" Vector__XXX

BO_ 2418311444 BMU_TransmitVoltage_N_17_P_4: 8 Vector__XXX
 SG_ BMU_Voltage_C17_12 : 0|16@1+ (1,0) [0|0] "" Vector__XXX
 SG_ BMU_Voltage_C17_13 : 16|16@1+ (1,0) [0|0] "" Vector__XXX
 SG_ BMU_Voltage_Age_C17 : 48|16@1+ (1,0) [0|0] "" Vector__XXX

BO_ 2418311456 BMU_TransmitVoltage_N_18_P_0: 8 Vector__XXX
 SG_ BMU_Voltage_C18_0 : 0|16@1+ (1,0) [0|0] "" Vector__XXX
 SG_ BMU_Voltage_C18_1 : 16|16@1+ (1,0) [0|0] "" Vector__XXX
 SG_ BMU_Voltage_C18_2 : 32|16@1+ (1,0) [0|0] "" Vector__XXX
 SG_ BMU_Voltage_Age_C18 : 48|16@1+ (1,0) [0|0] "" Vector__XXX

BO_ 2418311457 BMU_TransmitVoltage_N_18_P_1: 8 Vector__XXX
 SG_ BMU_Voltage_C18_3 : 0|16@1+ (1,0) [0|0] "" Vector__XXX
 SG_ BMU_Voltage_C18_4 : 16|16@1+ (1,0) [0|0] "" Vector__XXX
 SG_ BMU_Voltage_C18_5 : 32|16@1+ (1,0) [0|0] "" Vector__XXX
 SG_ BMU_Voltage_Age_C18 : 48|16@1+ (1,0) [0|0] "" Vector__XXX

BO_ 2418311458 BMU_TransmitVoltage_N_18_P_2: 8 Vector__XXX
 SG_ BMU_Voltage_C18_6 : 0|16@1+ (1,0) [0|0] "" Vector__XXX
 SG_ BMU_Voltage_C18_7 : 16|16@1+ (1,0) [0|0] "" Vector__XXX
 SG_ BMU_Voltage_C18_8 : 32|16@1+ (1,0) [0|0] "" Vector__XXX
 SG_ BMU_Voltage_Age_C18 : 48|16@1+ (1,0) [0|0] "" Vector__XXX

BO_ 2418311459 BMU_TransmitVoltage_N_18_P_3: 8 Vector__XXX
 SG_ BMU_Voltage_C18_9 : 0|16@1+ (1,0) [0|0] "" Vector__XXX
 SG_ BMU_Voltage_C18_10 : 16|16@1+ (1,0) [0|0] "" Vector__XXX
 SG_ BMU_Voltage_C18_11 : 32|16@1+ (1,0) [0|0] "" Vector__XXX
 SG_ BMU_Voltage_Age_C18 : 48|16@1+ (1,0) [0|0] "" Vector__XXX

BO_ 2418311460 BMU_TransmitVoltage_N_18_P_4: 8 Vector__XXX
 SG_ BMU_Voltage_C18_12 : 0|16@1+ (1,0) [0|0] "" Vector__XXX
 SG_ BMU_Voltage_C18_13 : 16|16@1+ (1,0) [0|0] "" Vector__XXX
 SG_ BMU_Voltage_Age_C18 : 48|16@1+ (1,0) [0|0] "" Vector__XXX

BO_ 2418311472 BMU_TransmitVoltage_N_19_P_0: 8 Vector__XXX
 SG_ BMU_Voltage_C19_0 : 0|16@1+ (1,0) [0|0] "" Vector__XXX
 SG_ BMU_Voltage_C19_1 : 16|16@1+ (1,0) [0|0] "" Vector__XXX
 SG_ BMU_Voltage_C19_2 : 32|16@1+ (1,0) [0|0] "" Vector__XXX
 SG_ BMU_Voltage_Age_C19 : 48|16@1+ (1,0) [0|0] "" Vector__XXX

BO_ 2418311473 BMU_TransmitVoltage_N_19_P_1: 8 Vector__XXX
 SG_ BMU_Voltage_C19_3 : 0|16@1+ (1,0) [0|0] "" Vector__XXX
 SG_ BMU_Voltage_C19_4 : 16|16@1+ (1,0) [0|0] "" Vector__XXX
 SG_ BMU_Voltage_C19_5 : 32|16@1+ (1,0) [0|0] "" Vector__XXX
 SG_ BMU_Voltage_Age_C19 : 48|16@1+ (1,0) [0|0] "" Vector__XXX

BO_ 2418311474 BMU_TransmitVoltage_N_19_P_2: 8 Vector__XXX
 SG_ BMU_Voltage_C19_6 : 0|16@1+ (1,0) [0|0] "" Vector__XXX
 SG_ BMU_Voltage_C19_7 : 16|16@1+ (1,0) [0|0] "" Vector__XXX
 SG_ BMU_Voltage_C19_8 : 32|16@1+ (1,0) [0|0] "" Vector__XXX
 SG_ BMU_Voltage_Age_C19 : 48|16@1+ (1,0) [0|0] "" Vector__XXX

BO_ 2418311475 BMU_TransmitVoltage_N_19_P_3: 8 Vector__XXX
 SG_ BMU_Voltage_C19_9 : 0|16@1+ (1,0) [0|0] "" Vector__XXX
 SG_ BMU_Voltage_C19_10 : 16|16@1+ (1,0) [0|0] "" Vector__XXX
 SG_ BMU_Voltage_C19_11 : 32|16@1+ (1,0) [0|0] "" Vector__XXX
 SG_ BMU_Voltage_Age_C19 : 48|16@1+ (1,0) [0|0] "" Vector__XXX

BO_ 2418311476 BMU_TransmitVoltage_N_19_P_4: 8 Vector__XXX
 SG_ BMU_Voltage_C19_12 : 0|16@1+ (1,0) [0|0] "" Vector__XXX
 SG_ BMU_Voltage_C19_13 : 16|16@1+ (1,0) [0|0] "" Vector__XXX
 SG_ BMU_Voltage_Age_C19 : 48|16@1+ (1,0) [0|0] "" Vector__XXX

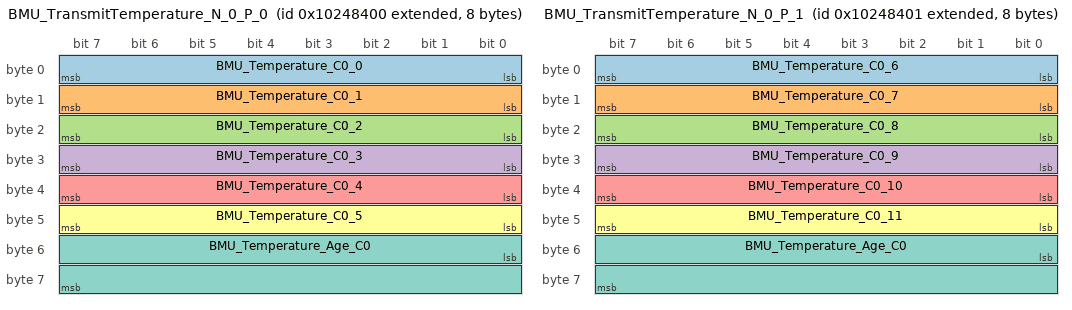
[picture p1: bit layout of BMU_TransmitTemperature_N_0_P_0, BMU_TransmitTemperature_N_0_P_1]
BO_ 2418312192 BMU_TransmitTemperature_N_0_P_0: 8 Vector__XXX
 SG_ BMU_Temperature_C0_0 : 0|8@1+ (1,0) [0|0] "" Vector__XXX
 SG_ BMU_Temperature_C0_1 : 8|8@1+ (1,0) [0|0] "" Vector__XXX
 SG_ BMU_Temperature_C0_2 : 16|8@1+ (1,0) [0|0] "" Vector__XXX
 SG_ BMU_Temperature_C0_3 : 24|8@1+ (1,0) [0|0] "" Vector__XXX
 SG_ BMU_Temperature_C0_4 : 32|8@1+ (1,0) [0|0] "" Vector__XXX
 SG_ BMU_Temperature_C0_5 : 40|8@1+ (1,0) [0|0] "" Vector__XXX
 SG_ BMU_Temperature_Age_C0 : 48|16@1+ (1,0) [0|0] "" Vector__XXX

BO_ 2418312193 BMU_TransmitTemperature_N_0_P_1: 8 Vector__XXX
 SG_ BMU_Temperature_C0_6 : 0|8@1+ (1,0) [0|0] "" Vector__XXX
 SG_ BMU_Temperature_C0_7 : 8|8@1+ (1,0) [0|0] "" Vector__XXX
 SG_ BMU_Temperature_C0_8 : 16|8@1+ (1,0) [0|0] "" Vector__XXX
 SG_ BMU_Temperature_C0_9 : 24|8@1+ (1,0) [0|0] "" Vector__XXX
 SG_ BMU_Temperature_C0_10 : 32|8@1+ (1,0) [0|0] "" Vector__XXX
 SG_ BMU_Temperature_C0_11 : 40|8@1+ (1,0) [0|0] "" Vector__XXX
 SG_ BMU_Temperature_Age_C0 : 48|16@1+ (1,0) [0|0] "" Vector__XXX

BO_ 2418312194 BMU_TransmitTemperature_N_0_P_2: 8 Vector__XXX
 SG_ BMU_Temperature_C0_12 : 0|8@1+ (1,0) [0|0] "" Vector__XXX
 SG_ BMU_Temperature_C0_13 : 8|8@1+ (1,0) [0|0] "" Vector__XXX
 SG_ BMU_Temperature_C0_14 : 16|8@1+ (1,0) [0|0] "" Vector__XXX
 SG_ BMU_Temperature_C0_15 : 24|8@1+ (1,0) [0|0] "" Vector__XXX
 SG_ BMU_Temperature_Age_C0 : 48|16@1+ (1,0) [0|0] "" Vector__XXX

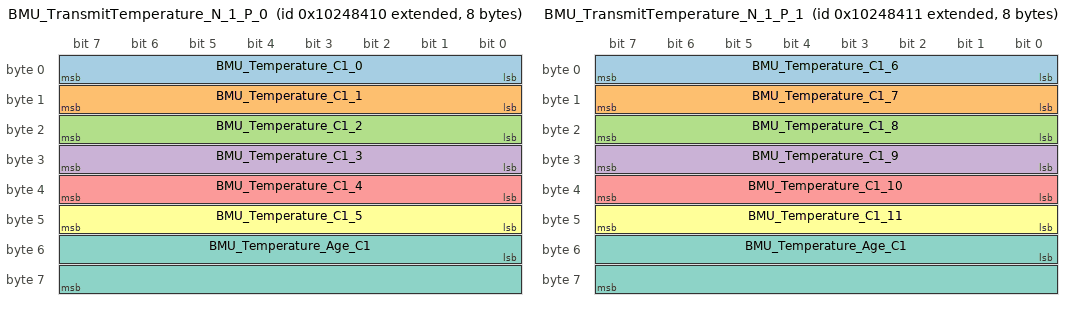
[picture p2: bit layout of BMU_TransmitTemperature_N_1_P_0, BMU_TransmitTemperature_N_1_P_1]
BO_ 2418312208 BMU_TransmitTemperature_N_1_P_0: 8 Vector__XXX
 SG_ BMU_Temperature_C1_0 : 0|8@1+ (1,0) [0|0] "" Vector__XXX
 SG_ BMU_Temperature_C1_1 : 8|8@1+ (1,0) [0|0] "" Vector__XXX
 SG_ BMU_Temperature_C1_2 : 16|8@1+ (1,0) [0|0] "" Vector__XXX
 SG_ BMU_Temperature_C1_3 : 24|8@1+ (1,0) [0|0] "" Vector__XXX
 SG_ BMU_Temperature_C1_4 : 32|8@1+ (1,0) [0|0] "" Vector__XXX
 SG_ BMU_Temperature_C1_5 : 40|8@1+ (1,0) [0|0] "" Vector__XXX
 SG_ BMU_Temperature_Age_C1 : 48|16@1+ (1,0) [0|0] "" Vector__XXX

BO_ 2418312209 BMU_TransmitTemperature_N_1_P_1: 8 Vector__XXX
 SG_ BMU_Temperature_C1_6 : 0|8@1+ (1,0) [0|0] "" Vector__XXX
 SG_ BMU_Temperature_C1_7 : 8|8@1+ (1,0) [0|0] "" Vector__XXX
 SG_ BMU_Temperature_C1_8 : 16|8@1+ (1,0) [0|0] "" Vector__XXX
 SG_ BMU_Temperature_C1_9 : 24|8@1+ (1,0) [0|0] "" Vector__XXX
 SG_ BMU_Temperature_C1_10 : 32|8@1+ (1,0) [0|0] "" Vector__XXX
 SG_ BMU_Temperature_C1_11 : 40|8@1+ (1,0) [0|0] "" Vector__XXX
 SG_ BMU_Temperature_Age_C1 : 48|16@1+ (1,0) [0|0] "" Vector__XXX

BO_ 2418312210 BMU_TransmitTemperature_N_1_P_2: 8 Vector__XXX
 SG_ BMU_Temperature_C1_12 : 0|8@1+ (1,0) [0|0] "" Vector__XXX
 SG_ BMU_Temperature_C1_13 : 8|8@1+ (1,0) [0|0] "" Vector__XXX
 SG_ BMU_Temperature_C1_14 : 16|8@1+ (1,0) [0|0] "" Vector__XXX
 SG_ BMU_Temperature_C1_15 : 24|8@1+ (1,0) [0|0] "" Vector__XXX
 SG_ BMU_Temperature_Age_C1 : 48|16@1+ (1,0) [0|0] "" Vector__XXX

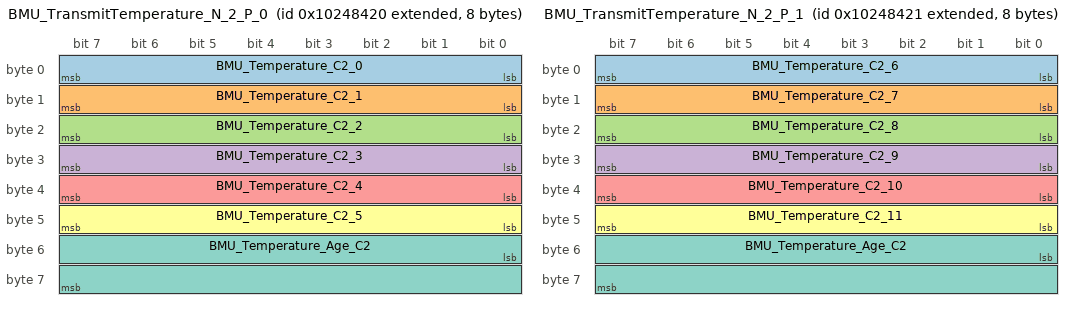
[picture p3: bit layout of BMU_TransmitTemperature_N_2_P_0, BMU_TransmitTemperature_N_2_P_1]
BO_ 2418312224 BMU_TransmitTemperature_N_2_P_0: 8 Vector__XXX
 SG_ BMU_Temperature_C2_0 : 0|8@1+ (1,0) [0|0] "" Vector__XXX
 SG_ BMU_Temperature_C2_1 : 8|8@1+ (1,0) [0|0] "" Vector__XXX
 SG_ BMU_Temperature_C2_2 : 16|8@1+ (1,0) [0|0] "" Vector__XXX
 SG_ BMU_Temperature_C2_3 : 24|8@1+ (1,0) [0|0] "" Vector__XXX
 SG_ BMU_Temperature_C2_4 : 32|8@1+ (1,0) [0|0] "" Vector__XXX
 SG_ BMU_Temperature_C2_5 : 40|8@1+ (1,0) [0|0] "" Vector__XXX
 SG_ BMU_Temperature_Age_C2 : 48|16@1+ (1,0) [0|0] "" Vector__XXX

BO_ 2418312225 BMU_TransmitTemperature_N_2_P_1: 8 Vector__XXX
 SG_ BMU_Temperature_C2_6 : 0|8@1+ (1,0) [0|0] "" Vector__XXX
 SG_ BMU_Temperature_C2_7 : 8|8@1+ (1,0) [0|0] "" Vector__XXX
 SG_ BMU_Temperature_C2_8 : 16|8@1+ (1,0) [0|0] "" Vector__XXX
 SG_ BMU_Temperature_C2_9 : 24|8@1+ (1,0) [0|0] "" Vector__XXX
 SG_ BMU_Temperature_C2_10 : 32|8@1+ (1,0) [0|0] "" Vector__XXX
 SG_ BMU_Temperature_C2_11 : 40|8@1+ (1,0) [0|0] "" Vector__XXX
 SG_ BMU_Temperature_Age_C2 : 48|16@1+ (1,0) [0|0] "" Vector__XXX

BO_ 2418312226 BMU_TransmitTemperature_N_2_P_2: 8 Vector__XXX
 SG_ BMU_Temperature_C2_12 : 0|8@1+ (1,0) [0|0] "" Vector__XXX
 SG_ BMU_Temperature_C2_13 : 8|8@1+ (1,0) [0|0] "" Vector__XXX
 SG_ BMU_Temperature_C2_14 : 16|8@1+ (1,0) [0|0] "" Vector__XXX
 SG_ BMU_Temperature_C2_15 : 24|8@1+ (1,0) [0|0] "" Vector__XXX
 SG_ BMU_Temperature_Age_C2 : 48|16@1+ (1,0) [0|0] "" Vector__XXX

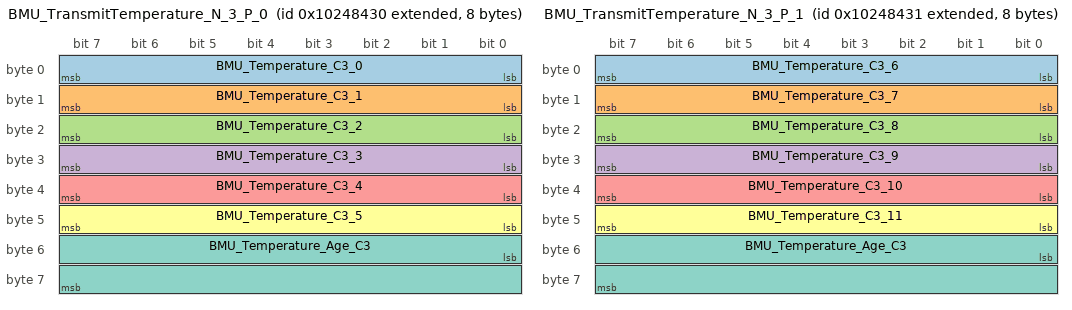
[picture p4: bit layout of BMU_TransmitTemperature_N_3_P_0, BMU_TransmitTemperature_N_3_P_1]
BO_ 2418312240 BMU_TransmitTemperature_N_3_P_0: 8 Vector__XXX
 SG_ BMU_Temperature_C3_0 : 0|8@1+ (1,0) [0|0] "" Vector__XXX
 SG_ BMU_Temperature_C3_1 : 8|8@1+ (1,0) [0|0] "" Vector__XXX
 SG_ BMU_Temperature_C3_2 : 16|8@1+ (1,0) [0|0] "" Vector__XXX
 SG_ BMU_Temperature_C3_3 : 24|8@1+ (1,0) [0|0] "" Vector__XXX
 SG_ BMU_Temperature_C3_4 : 32|8@1+ (1,0) [0|0] "" Vector__XXX
 SG_ BMU_Temperature_C3_5 : 40|8@1+ (1,0) [0|0] "" Vector__XXX
 SG_ BMU_Temperature_Age_C3 : 48|16@1+ (1,0) [0|0] "" Vector__XXX

BO_ 2418312241 BMU_TransmitTemperature_N_3_P_1: 8 Vector__XXX
 SG_ BMU_Temperature_C3_6 : 0|8@1+ (1,0) [0|0] "" Vector__XXX
 SG_ BMU_Temperature_C3_7 : 8|8@1+ (1,0) [0|0] "" Vector__XXX
 SG_ BMU_Temperature_C3_8 : 16|8@1+ (1,0) [0|0] "" Vector__XXX
 SG_ BMU_Temperature_C3_9 : 24|8@1+ (1,0) [0|0] "" Vector__XXX
 SG_ BMU_Temperature_C3_10 : 32|8@1+ (1,0) [0|0] "" Vector__XXX
 SG_ BMU_Temperature_C3_11 : 40|8@1+ (1,0) [0|0] "" Vector__XXX
 SG_ BMU_Temperature_Age_C3 : 48|16@1+ (1,0) [0|0] "" Vector__XXX

BO_ 2418312242 BMU_TransmitTemperature_N_3_P_2: 8 Vector__XXX
 SG_ BMU_Temperature_C3_12 : 0|8@1+ (1,0) [0|0] "" Vector__XXX
 SG_ BMU_Temperature_C3_13 : 8|8@1+ (1,0) [0|0] "" Vector__XXX
 SG_ BMU_Temperature_C3_14 : 16|8@1+ (1,0) [0|0] "" Vector__XXX
 SG_ BMU_Temperature_C3_15 : 24|8@1+ (1,0) [0|0] "" Vector__XXX
 SG_ BMU_Temperature_Age_C3 : 48|16@1+ (1,0) [0|0] "" Vector__XXX

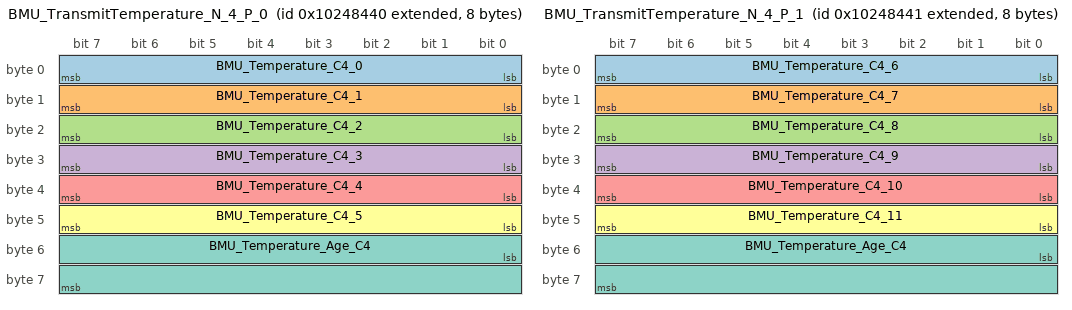
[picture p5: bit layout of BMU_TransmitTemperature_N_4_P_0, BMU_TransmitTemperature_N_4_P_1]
BO_ 2418312256 BMU_TransmitTemperature_N_4_P_0: 8 Vector__XXX
 SG_ BMU_Temperature_C4_0 : 0|8@1+ (1,0) [0|0] "" Vector__XXX
 SG_ BMU_Temperature_C4_1 : 8|8@1+ (1,0) [0|0] "" Vector__XXX
 SG_ BMU_Temperature_C4_2 : 16|8@1+ (1,0) [0|0] "" Vector__XXX
 SG_ BMU_Temperature_C4_3 : 24|8@1+ (1,0) [0|0] "" Vector__XXX
 SG_ BMU_Temperature_C4_4 : 32|8@1+ (1,0) [0|0] "" Vector__XXX
 SG_ BMU_Temperature_C4_5 : 40|8@1+ (1,0) [0|0] "" Vector__XXX
 SG_ BMU_Temperature_Age_C4 : 48|16@1+ (1,0) [0|0] "" Vector__XXX

BO_ 2418312257 BMU_TransmitTemperature_N_4_P_1: 8 Vector__XXX
 SG_ BMU_Temperature_C4_6 : 0|8@1+ (1,0) [0|0] "" Vector__XXX
 SG_ BMU_Temperature_C4_7 : 8|8@1+ (1,0) [0|0] "" Vector__XXX
 SG_ BMU_Temperature_C4_8 : 16|8@1+ (1,0) [0|0] "" Vector__XXX
 SG_ BMU_Temperature_C4_9 : 24|8@1+ (1,0) [0|0] "" Vector__XXX
 SG_ BMU_Temperature_C4_10 : 32|8@1+ (1,0) [0|0] "" Vector__XXX
 SG_ BMU_Temperature_C4_11 : 40|8@1+ (1,0) [0|0] "" Vector__XXX
 SG_ BMU_Temperature_Age_C4 : 48|16@1+ (1,0) [0|0] "" Vector__XXX

BO_ 2418312258 BMU_TransmitTemperature_N_4_P_2: 8 Vector__XXX
 SG_ BMU_Temperature_C4_12 : 0|8@1+ (1,0) [0|0] "" Vector__XXX
 SG_ BMU_Temperature_C4_13 : 8|8@1+ (1,0) [0|0] "" Vector__XXX
 SG_ BMU_Temperature_C4_14 : 16|8@1+ (1,0) [0|0] "" Vector__XXX
 SG_ BMU_Temperature_C4_15 : 24|8@1+ (1,0) [0|0] "" Vector__XXX
 SG_ BMU_Temperature_Age_C4 : 48|16@1+ (1,0) [0|0] "" Vector__XXX

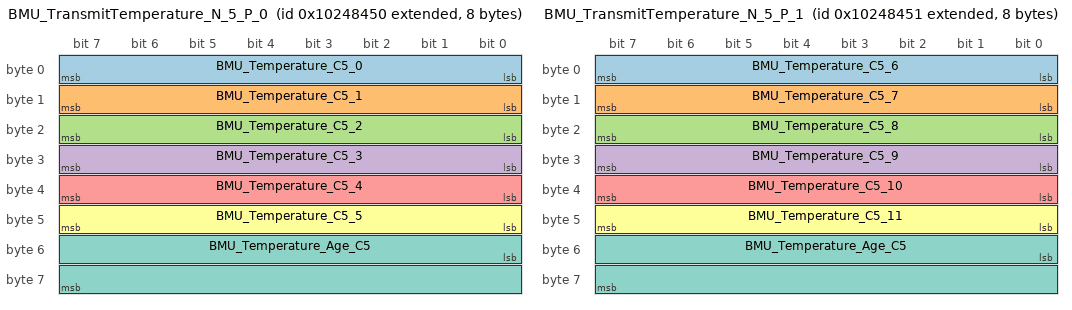
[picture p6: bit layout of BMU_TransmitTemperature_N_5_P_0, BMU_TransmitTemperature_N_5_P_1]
BO_ 2418312272 BMU_TransmitTemperature_N_5_P_0: 8 Vector__XXX
 SG_ BMU_Temperature_C5_0 : 0|8@1+ (1,0) [0|0] "" Vector__XXX
 SG_ BMU_Temperature_C5_1 : 8|8@1+ (1,0) [0|0] "" Vector__XXX
 SG_ BMU_Temperature_C5_2 : 16|8@1+ (1,0) [0|0] "" Vector__XXX
 SG_ BMU_Temperature_C5_3 : 24|8@1+ (1,0) [0|0] "" Vector__XXX
 SG_ BMU_Temperature_C5_4 : 32|8@1+ (1,0) [0|0] "" Vector__XXX
 SG_ BMU_Temperature_C5_5 : 40|8@1+ (1,0) [0|0] "" Vector__XXX
 SG_ BMU_Temperature_Age_C5 : 48|16@1+ (1,0) [0|0] "" Vector__XXX

BO_ 2418312273 BMU_TransmitTemperature_N_5_P_1: 8 Vector__XXX
 SG_ BMU_Temperature_C5_6 : 0|8@1+ (1,0) [0|0] "" Vector__XXX
 SG_ BMU_Temperature_C5_7 : 8|8@1+ (1,0) [0|0] "" Vector__XXX
 SG_ BMU_Temperature_C5_8 : 16|8@1+ (1,0) [0|0] "" Vector__XXX
 SG_ BMU_Temperature_C5_9 : 24|8@1+ (1,0) [0|0] "" Vector__XXX
 SG_ BMU_Temperature_C5_10 : 32|8@1+ (1,0) [0|0] "" Vector__XXX
 SG_ BMU_Temperature_C5_11 : 40|8@1+ (1,0) [0|0] "" Vector__XXX
 SG_ BMU_Temperature_Age_C5 : 48|16@1+ (1,0) [0|0] "" Vector__XXX

BO_ 2418312274 BMU_TransmitTemperature_N_5_P_2: 8 Vector__XXX
 SG_ BMU_Temperature_C5_12 : 0|8@1+ (1,0) [0|0] "" Vector__XXX
 SG_ BMU_Temperature_C5_13 : 8|8@1+ (1,0) [0|0] "" Vector__XXX
 SG_ BMU_Temperature_C5_14 : 16|8@1+ (1,0) [0|0] "" Vector__XXX
 SG_ BMU_Temperature_C5_15 : 24|8@1+ (1,0) [0|0] "" Vector__XXX
 SG_ BMU_Temperature_Age_C5 : 48|16@1+ (1,0) [0|0] "" Vector__XXX

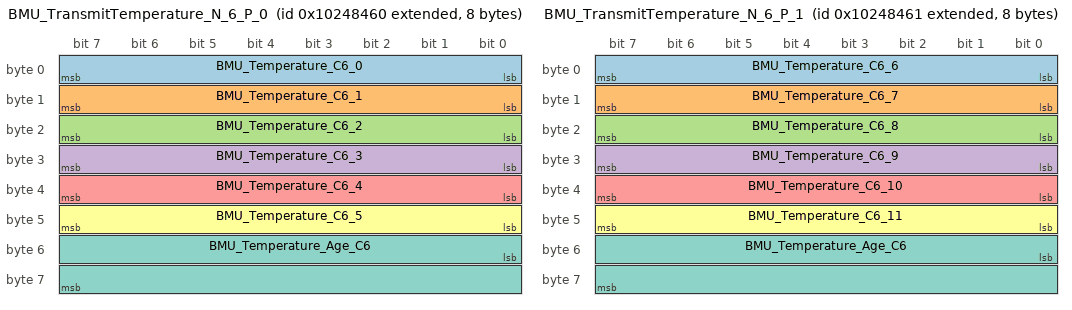
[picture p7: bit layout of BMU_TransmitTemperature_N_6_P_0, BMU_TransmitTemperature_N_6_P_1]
BO_ 2418312288 BMU_TransmitTemperature_N_6_P_0: 8 Vector__XXX
 SG_ BMU_Temperature_C6_0 : 0|8@1+ (1,0) [0|0] "" Vector__XXX
 SG_ BMU_Temperature_C6_1 : 8|8@1+ (1,0) [0|0] "" Vector__XXX
 SG_ BMU_Temperature_C6_2 : 16|8@1+ (1,0) [0|0] "" Vector__XXX
 SG_ BMU_Temperature_C6_3 : 24|8@1+ (1,0) [0|0] "" Vector__XXX
 SG_ BMU_Temperature_C6_4 : 32|8@1+ (1,0) [0|0] "" Vector__XXX
 SG_ BMU_Temperature_C6_5 : 40|8@1+ (1,0) [0|0] "" Vector__XXX
 SG_ BMU_Temperature_Age_C6 : 48|16@1+ (1,0) [0|0] "" Vector__XXX

BO_ 2418312289 BMU_TransmitTemperature_N_6_P_1: 8 Vector__XXX
 SG_ BMU_Temperature_C6_6 : 0|8@1+ (1,0) [0|0] "" Vector__XXX
 SG_ BMU_Temperature_C6_7 : 8|8@1+ (1,0) [0|0] "" Vector__XXX
 SG_ BMU_Temperature_C6_8 : 16|8@1+ (1,0) [0|0] "" Vector__XXX
 SG_ BMU_Temperature_C6_9 : 24|8@1+ (1,0) [0|0] "" Vector__XXX
 SG_ BMU_Temperature_C6_10 : 32|8@1+ (1,0) [0|0] "" Vector__XXX
 SG_ BMU_Temperature_C6_11 : 40|8@1+ (1,0) [0|0] "" Vector__XXX
 SG_ BMU_Temperature_Age_C6 : 48|16@1+ (1,0) [0|0] "" Vector__XXX

BO_ 2418312290 BMU_TransmitTemperature_N_6_P_2: 8 Vector__XXX
 SG_ BMU_Temperature_C6_12 : 0|8@1+ (1,0) [0|0] "" Vector__XXX
 SG_ BMU_Temperature_C6_13 : 8|8@1+ (1,0) [0|0] "" Vector__XXX
 SG_ BMU_Temperature_C6_14 : 16|8@1+ (1,0) [0|0] "" Vector__XXX
 SG_ BMU_Temperature_C6_15 : 24|8@1+ (1,0) [0|0] "" Vector__XXX
 SG_ BMU_Temperature_Age_C6 : 48|16@1+ (1,0) [0|0] "" Vector__XXX

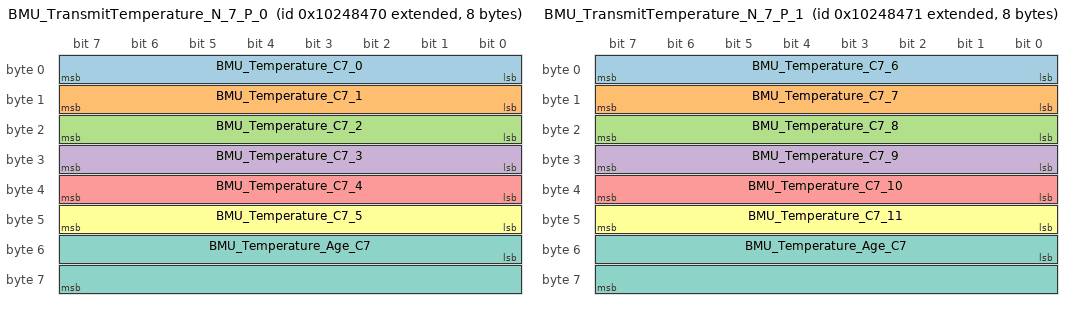
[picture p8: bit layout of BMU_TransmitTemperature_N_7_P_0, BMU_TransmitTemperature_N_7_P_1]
BO_ 2418312304 BMU_TransmitTemperature_N_7_P_0: 8 Vector__XXX
 SG_ BMU_Temperature_C7_0 : 0|8@1+ (1,0) [0|0] "" Vector__XXX
 SG_ BMU_Temperature_C7_1 : 8|8@1+ (1,0) [0|0] "" Vector__XXX
 SG_ BMU_Temperature_C7_2 : 16|8@1+ (1,0) [0|0] "" Vector__XXX
 SG_ BMU_Temperature_C7_3 : 24|8@1+ (1,0) [0|0] "" Vector__XXX
 SG_ BMU_Temperature_C7_4 : 32|8@1+ (1,0) [0|0] "" Vector__XXX
 SG_ BMU_Temperature_C7_5 : 40|8@1+ (1,0) [0|0] "" Vector__XXX
 SG_ BMU_Temperature_Age_C7 : 48|16@1+ (1,0) [0|0] "" Vector__XXX

BO_ 2418312305 BMU_TransmitTemperature_N_7_P_1: 8 Vector__XXX
 SG_ BMU_Temperature_C7_6 : 0|8@1+ (1,0) [0|0] "" Vector__XXX
 SG_ BMU_Temperature_C7_7 : 8|8@1+ (1,0) [0|0] "" Vector__XXX
 SG_ BMU_Temperature_C7_8 : 16|8@1+ (1,0) [0|0] "" Vector__XXX
 SG_ BMU_Temperature_C7_9 : 24|8@1+ (1,0) [0|0] "" Vector__XXX
 SG_ BMU_Temperature_C7_10 : 32|8@1+ (1,0) [0|0] "" Vector__XXX
 SG_ BMU_Temperature_C7_11 : 40|8@1+ (1,0) [0|0] "" Vector__XXX
 SG_ BMU_Temperature_Age_C7 : 48|16@1+ (1,0) [0|0] "" Vector__XXX

BO_ 2418312306 BMU_TransmitTemperature_N_7_P_2: 8 Vector__XXX
 SG_ BMU_Temperature_C7_12 : 0|8@1+ (1,0) [0|0] "" Vector__XXX
 SG_ BMU_Temperature_C7_13 : 8|8@1+ (1,0) [0|0] "" Vector__XXX
 SG_ BMU_Temperature_C7_14 : 16|8@1+ (1,0) [0|0] "" Vector__XXX
 SG_ BMU_Temperature_C7_15 : 24|8@1+ (1,0) [0|0] "" Vector__XXX
 SG_ BMU_Temperature_Age_C7 : 48|16@1+ (1,0) [0|0] "" Vector__XXX

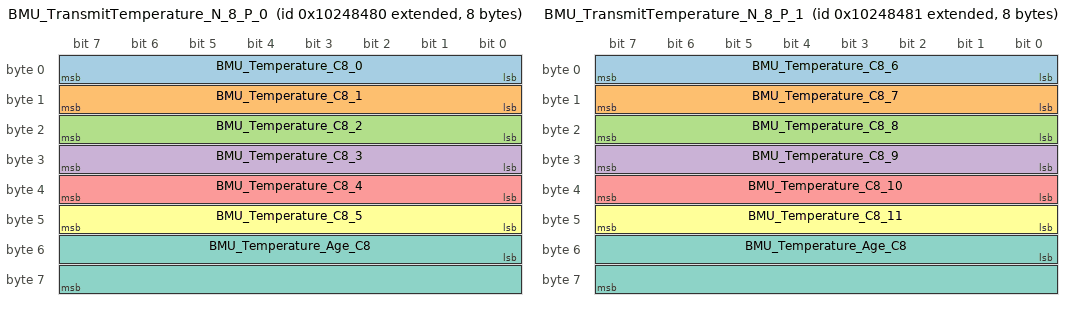
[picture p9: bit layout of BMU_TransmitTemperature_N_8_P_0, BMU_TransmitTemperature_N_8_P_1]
BO_ 2418312320 BMU_TransmitTemperature_N_8_P_0: 8 Vector__XXX
 SG_ BMU_Temperature_C8_0 : 0|8@1+ (1,0) [0|0] "" Vector__XXX
 SG_ BMU_Temperature_C8_1 : 8|8@1+ (1,0) [0|0] "" Vector__XXX
 SG_ BMU_Temperature_C8_2 : 16|8@1+ (1,0) [0|0] "" Vector__XXX
 SG_ BMU_Temperature_C8_3 : 24|8@1+ (1,0) [0|0] "" Vector__XXX
 SG_ BMU_Temperature_C8_4 : 32|8@1+ (1,0) [0|0] "" Vector__XXX
 SG_ BMU_Temperature_C8_5 : 40|8@1+ (1,0) [0|0] "" Vector__XXX
 SG_ BMU_Temperature_Age_C8 : 48|16@1+ (1,0) [0|0] "" Vector__XXX

BO_ 2418312321 BMU_TransmitTemperature_N_8_P_1: 8 Vector__XXX
 SG_ BMU_Temperature_C8_6 : 0|8@1+ (1,0) [0|0] "" Vector__XXX
 SG_ BMU_Temperature_C8_7 : 8|8@1+ (1,0) [0|0] "" Vector__XXX
 SG_ BMU_Temperature_C8_8 : 16|8@1+ (1,0) [0|0] "" Vector__XXX
 SG_ BMU_Temperature_C8_9 : 24|8@1+ (1,0) [0|0] "" Vector__XXX
 SG_ BMU_Temperature_C8_10 : 32|8@1+ (1,0) [0|0] "" Vector__XXX
 SG_ BMU_Temperature_C8_11 : 40|8@1+ (1,0) [0|0] "" Vector__XXX
 SG_ BMU_Temperature_Age_C8 : 48|16@1+ (1,0) [0|0] "" Vector__XXX

BO_ 2418312322 BMU_TransmitTemperature_N_8_P_2: 8 Vector__XXX
 SG_ BMU_Temperature_C8_12 : 0|8@1+ (1,0) [0|0] "" Vector__XXX
 SG_ BMU_Temperature_C8_13 : 8|8@1+ (1,0) [0|0] "" Vector__XXX
 SG_ BMU_Temperature_C8_14 : 16|8@1+ (1,0) [0|0] "" Vector__XXX
 SG_ BMU_Temperature_C8_15 : 24|8@1+ (1,0) [0|0] "" Vector__XXX
 SG_ BMU_Temperature_Age_C8 : 48|16@1+ (1,0) [0|0] "" Vector__XXX

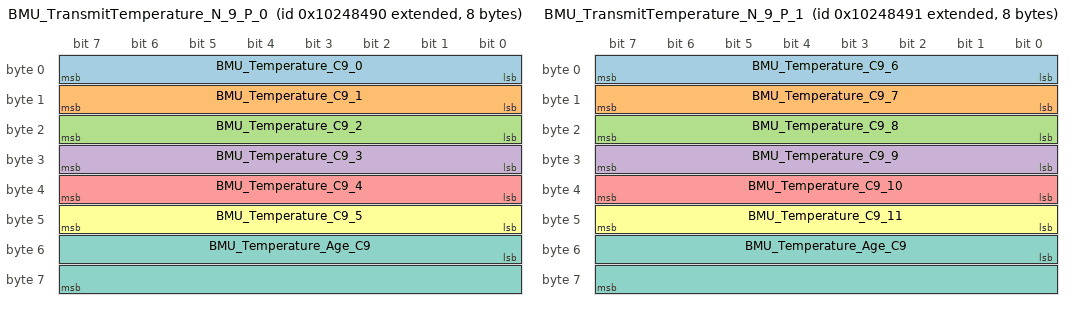
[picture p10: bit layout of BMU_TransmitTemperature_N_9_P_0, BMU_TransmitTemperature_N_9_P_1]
BO_ 2418312336 BMU_TransmitTemperature_N_9_P_0: 8 Vector__XXX
 SG_ BMU_Temperature_C9_0 : 0|8@1+ (1,0) [0|0] "" Vector__XXX
 SG_ BMU_Temperature_C9_1 : 8|8@1+ (1,0) [0|0] "" Vector__XXX
 SG_ BMU_Temperature_C9_2 : 16|8@1+ (1,0) [0|0] "" Vector__XXX
 SG_ BMU_Temperature_C9_3 : 24|8@1+ (1,0) [0|0] "" Vector__XXX
 SG_ BMU_Temperature_C9_4 : 32|8@1+ (1,0) [0|0] "" Vector__XXX
 SG_ BMU_Temperature_C9_5 : 40|8@1+ (1,0) [0|0] "" Vector__XXX
 SG_ BMU_Temperature_Age_C9 : 48|16@1+ (1,0) [0|0] "" Vector__XXX

BO_ 2418312337 BMU_TransmitTemperature_N_9_P_1: 8 Vector__XXX
 SG_ BMU_Temperature_C9_6 : 0|8@1+ (1,0) [0|0] "" Vector__XXX
 SG_ BMU_Temperature_C9_7 : 8|8@1+ (1,0) [0|0] "" Vector__XXX
 SG_ BMU_Temperature_C9_8 : 16|8@1+ (1,0) [0|0] "" Vector__XXX
 SG_ BMU_Temperature_C9_9 : 24|8@1+ (1,0) [0|0] "" Vector__XXX
 SG_ BMU_Temperature_C9_10 : 32|8@1+ (1,0) [0|0] "" Vector__XXX
 SG_ BMU_Temperature_C9_11 : 40|8@1+ (1,0) [0|0] "" Vector__XXX
 SG_ BMU_Temperature_Age_C9 : 48|16@1+ (1,0) [0|0] "" Vector__XXX

BO_ 2418312338 BMU_TransmitTemperature_N_9_P_2: 8 Vector__XXX
 SG_ BMU_Temperature_C9_12 : 0|8@1+ (1,0) [0|0] "" Vector__XXX
 SG_ BMU_Temperature_C9_13 : 8|8@1+ (1,0) [0|0] "" Vector__XXX
 SG_ BMU_Temperature_C9_14 : 16|8@1+ (1,0) [0|0] "" Vector__XXX
 SG_ BMU_Temperature_C9_15 : 24|8@1+ (1,0) [0|0] "" Vector__XXX
 SG_ BMU_Temperature_Age_C9 : 48|16@1+ (1,0) [0|0] "" Vector__XXX

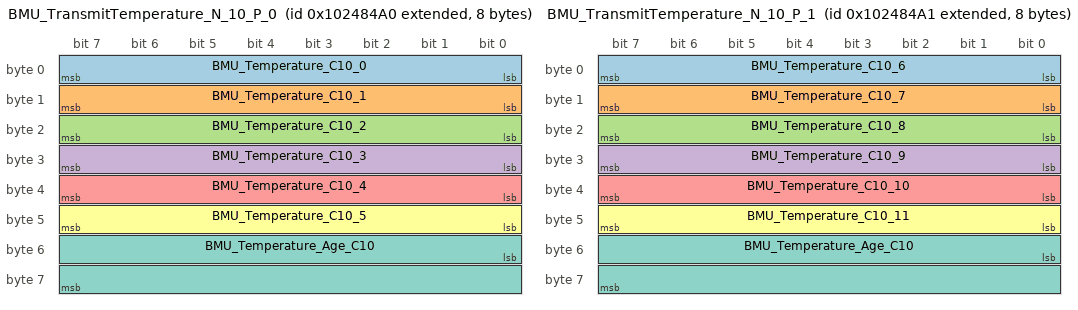
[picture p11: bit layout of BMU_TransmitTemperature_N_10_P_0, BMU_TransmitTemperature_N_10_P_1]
BO_ 2418312352 BMU_TransmitTemperature_N_10_P_0: 8 Vector__XXX
 SG_ BMU_Temperature_C10_0 : 0|8@1+ (1,0) [0|0] "" Vector__XXX
 SG_ BMU_Temperature_C10_1 : 8|8@1+ (1,0) [0|0] "" Vector__XXX
 SG_ BMU_Temperature_C10_2 : 16|8@1+ (1,0) [0|0] "" Vector__XXX
 SG_ BMU_Temperature_C10_3 : 24|8@1+ (1,0) [0|0] "" Vector__XXX
 SG_ BMU_Temperature_C10_4 : 32|8@1+ (1,0) [0|0] "" Vector__XXX
 SG_ BMU_Temperature_C10_5 : 40|8@1+ (1,0) [0|0] "" Vector__XXX
 SG_ BMU_Temperature_Age_C10 : 48|16@1+ (1,0) [0|0] "" Vector__XXX

BO_ 2418312353 BMU_TransmitTemperature_N_10_P_1: 8 Vector__XXX
 SG_ BMU_Temperature_C10_6 : 0|8@1+ (1,0) [0|0] "" Vector__XXX
 SG_ BMU_Temperature_C10_7 : 8|8@1+ (1,0) [0|0] "" Vector__XXX
 SG_ BMU_Temperature_C10_8 : 16|8@1+ (1,0) [0|0] "" Vector__XXX
 SG_ BMU_Temperature_C10_9 : 24|8@1+ (1,0) [0|0] "" Vector__XXX
 SG_ BMU_Temperature_C10_10 : 32|8@1+ (1,0) [0|0] "" Vector__XXX
 SG_ BMU_Temperature_C10_11 : 40|8@1+ (1,0) [0|0] "" Vector__XXX
 SG_ BMU_Temperature_Age_C10 : 48|16@1+ (1,0) [0|0] "" Vector__XXX

BO_ 2418312354 BMU_TransmitTemperature_N_10_P_2: 8 Vector__XXX
 SG_ BMU_Temperature_C10_12 : 0|8@1+ (1,0) [0|0] "" Vector__XXX
 SG_ BMU_Temperature_C10_13 : 8|8@1+ (1,0) [0|0] "" Vector__XXX
 SG_ BMU_Temperature_C10_14 : 16|8@1+ (1,0) [0|0] "" Vector__XXX
 SG_ BMU_Temperature_C10_15 : 24|8@1+ (1,0) [0|0] "" Vector__XXX
 SG_ BMU_Temperature_Age_C10 : 48|16@1+ (1,0) [0|0] "" Vector__XXX

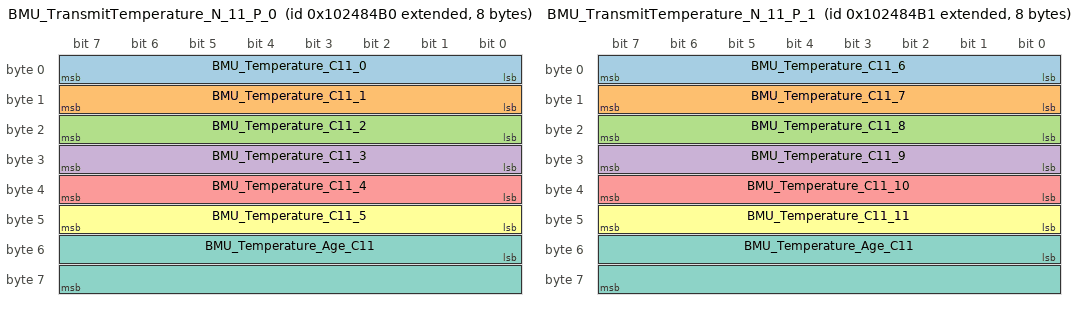
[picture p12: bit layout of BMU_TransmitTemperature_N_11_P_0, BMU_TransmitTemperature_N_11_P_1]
BO_ 2418312368 BMU_TransmitTemperature_N_11_P_0: 8 Vector__XXX
 SG_ BMU_Temperature_C11_0 : 0|8@1+ (1,0) [0|0] "" Vector__XXX
 SG_ BMU_Temperature_C11_1 : 8|8@1+ (1,0) [0|0] "" Vector__XXX
 SG_ BMU_Temperature_C11_2 : 16|8@1+ (1,0) [0|0] "" Vector__XXX
 SG_ BMU_Temperature_C11_3 : 24|8@1+ (1,0) [0|0] "" Vector__XXX
 SG_ BMU_Temperature_C11_4 : 32|8@1+ (1,0) [0|0] "" Vector__XXX
 SG_ BMU_Temperature_C11_5 : 40|8@1+ (1,0) [0|0] "" Vector__XXX
 SG_ BMU_Temperature_Age_C11 : 48|16@1+ (1,0) [0|0] "" Vector__XXX

BO_ 2418312369 BMU_TransmitTemperature_N_11_P_1: 8 Vector__XXX
 SG_ BMU_Temperature_C11_6 : 0|8@1+ (1,0) [0|0] "" Vector__XXX
 SG_ BMU_Temperature_C11_7 : 8|8@1+ (1,0) [0|0] "" Vector__XXX
 SG_ BMU_Temperature_C11_8 : 16|8@1+ (1,0) [0|0] "" Vector__XXX
 SG_ BMU_Temperature_C11_9 : 24|8@1+ (1,0) [0|0] "" Vector__XXX
 SG_ BMU_Temperature_C11_10 : 32|8@1+ (1,0) [0|0] "" Vector__XXX
 SG_ BMU_Temperature_C11_11 : 40|8@1+ (1,0) [0|0] "" Vector__XXX
 SG_ BMU_Temperature_Age_C11 : 48|16@1+ (1,0) [0|0] "" Vector__XXX

BO_ 2418312370 BMU_TransmitTemperature_N_11_P_2: 8 Vector__XXX
 SG_ BMU_Temperature_C11_12 : 0|8@1+ (1,0) [0|0] "" Vector__XXX
 SG_ BMU_Temperature_C11_13 : 8|8@1+ (1,0) [0|0] "" Vector__XXX
 SG_ BMU_Temperature_C11_14 : 16|8@1+ (1,0) [0|0] "" Vector__XXX
 SG_ BMU_Temperature_C11_15 : 24|8@1+ (1,0) [0|0] "" Vector__XXX
 SG_ BMU_Temperature_Age_C11 : 48|16@1+ (1,0) [0|0] "" Vector__XXX

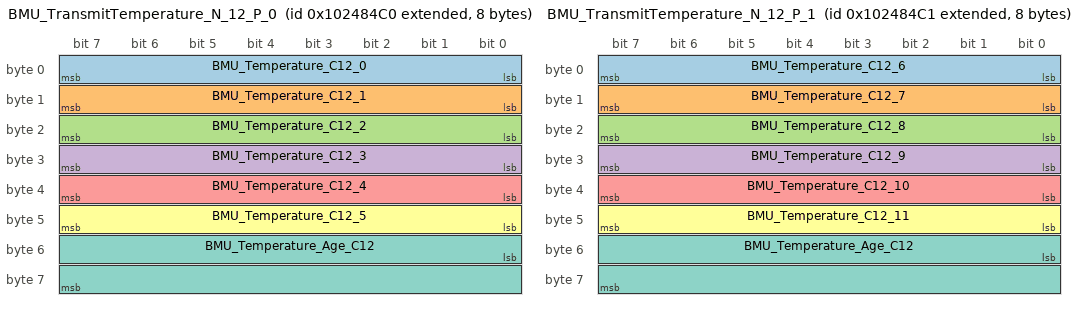
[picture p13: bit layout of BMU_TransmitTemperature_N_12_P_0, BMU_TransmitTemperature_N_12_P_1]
BO_ 2418312384 BMU_TransmitTemperature_N_12_P_0: 8 Vector__XXX
 SG_ BMU_Temperature_C12_0 : 0|8@1+ (1,0) [0|0] "" Vector__XXX
 SG_ BMU_Temperature_C12_1 : 8|8@1+ (1,0) [0|0] "" Vector__XXX
 SG_ BMU_Temperature_C12_2 : 16|8@1+ (1,0) [0|0] "" Vector__XXX
 SG_ BMU_Temperature_C12_3 : 24|8@1+ (1,0) [0|0] "" Vector__XXX
 SG_ BMU_Temperature_C12_4 : 32|8@1+ (1,0) [0|0] "" Vector__XXX
 SG_ BMU_Temperature_C12_5 : 40|8@1+ (1,0) [0|0] "" Vector__XXX
 SG_ BMU_Temperature_Age_C12 : 48|16@1+ (1,0) [0|0] "" Vector__XXX

BO_ 2418312385 BMU_TransmitTemperature_N_12_P_1: 8 Vector__XXX
 SG_ BMU_Temperature_C12_6 : 0|8@1+ (1,0) [0|0] "" Vector__XXX
 SG_ BMU_Temperature_C12_7 : 8|8@1+ (1,0) [0|0] "" Vector__XXX
 SG_ BMU_Temperature_C12_8 : 16|8@1+ (1,0) [0|0] "" Vector__XXX
 SG_ BMU_Temperature_C12_9 : 24|8@1+ (1,0) [0|0] "" Vector__XXX
 SG_ BMU_Temperature_C12_10 : 32|8@1+ (1,0) [0|0] "" Vector__XXX
 SG_ BMU_Temperature_C12_11 : 40|8@1+ (1,0) [0|0] "" Vector__XXX
 SG_ BMU_Temperature_Age_C12 : 48|16@1+ (1,0) [0|0] "" Vector__XXX

BO_ 2418312386 BMU_TransmitTemperature_N_12_P_2: 8 Vector__XXX
 SG_ BMU_Temperature_C12_12 : 0|8@1+ (1,0) [0|0] "" Vector__XXX
 SG_ BMU_Temperature_C12_13 : 8|8@1+ (1,0) [0|0] "" Vector__XXX
 SG_ BMU_Temperature_C12_14 : 16|8@1+ (1,0) [0|0] "" Vector__XXX
 SG_ BMU_Temperature_C12_15 : 24|8@1+ (1,0) [0|0] "" Vector__XXX
 SG_ BMU_Temperature_Age_C12 : 48|16@1+ (1,0) [0|0] "" Vector__XXX

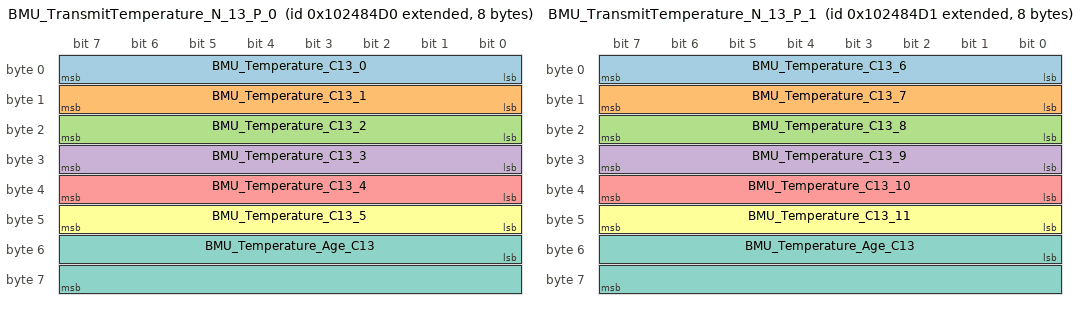
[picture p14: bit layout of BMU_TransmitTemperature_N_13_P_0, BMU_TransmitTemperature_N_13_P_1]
BO_ 2418312400 BMU_TransmitTemperature_N_13_P_0: 8 Vector__XXX
 SG_ BMU_Temperature_C13_0 : 0|8@1+ (1,0) [0|0] "" Vector__XXX
 SG_ BMU_Temperature_C13_1 : 8|8@1+ (1,0) [0|0] "" Vector__XXX
 SG_ BMU_Temperature_C13_2 : 16|8@1+ (1,0) [0|0] "" Vector__XXX
 SG_ BMU_Temperature_C13_3 : 24|8@1+ (1,0) [0|0] "" Vector__XXX
 SG_ BMU_Temperature_C13_4 : 32|8@1+ (1,0) [0|0] "" Vector__XXX
 SG_ BMU_Temperature_C13_5 : 40|8@1+ (1,0) [0|0] "" Vector__XXX
 SG_ BMU_Temperature_Age_C13 : 48|16@1+ (1,0) [0|0] "" Vector__XXX

BO_ 2418312401 BMU_TransmitTemperature_N_13_P_1: 8 Vector__XXX
 SG_ BMU_Temperature_C13_6 : 0|8@1+ (1,0) [0|0] "" Vector__XXX
 SG_ BMU_Temperature_C13_7 : 8|8@1+ (1,0) [0|0] "" Vector__XXX
 SG_ BMU_Temperature_C13_8 : 16|8@1+ (1,0) [0|0] "" Vector__XXX
 SG_ BMU_Temperature_C13_9 : 24|8@1+ (1,0) [0|0] "" Vector__XXX
 SG_ BMU_Temperature_C13_10 : 32|8@1+ (1,0) [0|0] "" Vector__XXX
 SG_ BMU_Temperature_C13_11 : 40|8@1+ (1,0) [0|0] "" Vector__XXX
 SG_ BMU_Temperature_Age_C13 : 48|16@1+ (1,0) [0|0] "" Vector__XXX

BO_ 2418312402 BMU_TransmitTemperature_N_13_P_2: 8 Vector__XXX
 SG_ BMU_Temperature_C13_12 : 0|8@1+ (1,0) [0|0] "" Vector__XXX
 SG_ BMU_Temperature_C13_13 : 8|8@1+ (1,0) [0|0] "" Vector__XXX
 SG_ BMU_Temperature_C13_14 : 16|8@1+ (1,0) [0|0] "" Vector__XXX
 SG_ BMU_Temperature_C13_15 : 24|8@1+ (1,0) [0|0] "" Vector__XXX
 SG_ BMU_Temperature_Age_C13 : 48|16@1+ (1,0) [0|0] "" Vector__XXX

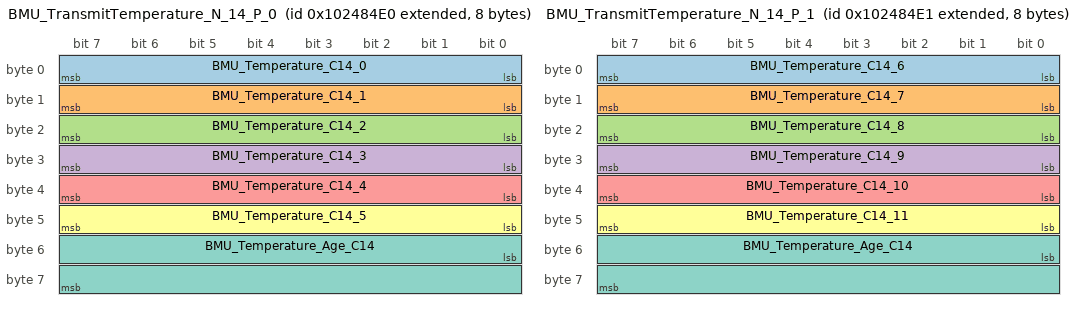
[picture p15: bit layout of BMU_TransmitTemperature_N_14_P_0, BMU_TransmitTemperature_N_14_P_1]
BO_ 2418312416 BMU_TransmitTemperature_N_14_P_0: 8 Vector__XXX
 SG_ BMU_Temperature_C14_0 : 0|8@1+ (1,0) [0|0] "" Vector__XXX
 SG_ BMU_Temperature_C14_1 : 8|8@1+ (1,0) [0|0] "" Vector__XXX
 SG_ BMU_Temperature_C14_2 : 16|8@1+ (1,0) [0|0] "" Vector__XXX
 SG_ BMU_Temperature_C14_3 : 24|8@1+ (1,0) [0|0] "" Vector__XXX
 SG_ BMU_Temperature_C14_4 : 32|8@1+ (1,0) [0|0] "" Vector__XXX
 SG_ BMU_Temperature_C14_5 : 40|8@1+ (1,0) [0|0] "" Vector__XXX
 SG_ BMU_Temperature_Age_C14 : 48|16@1+ (1,0) [0|0] "" Vector__XXX

BO_ 2418312417 BMU_TransmitTemperature_N_14_P_1: 8 Vector__XXX
 SG_ BMU_Temperature_C14_6 : 0|8@1+ (1,0) [0|0] "" Vector__XXX
 SG_ BMU_Temperature_C14_7 : 8|8@1+ (1,0) [0|0] "" Vector__XXX
 SG_ BMU_Temperature_C14_8 : 16|8@1+ (1,0) [0|0] "" Vector__XXX
 SG_ BMU_Temperature_C14_9 : 24|8@1+ (1,0) [0|0] "" Vector__XXX
 SG_ BMU_Temperature_C14_10 : 32|8@1+ (1,0) [0|0] "" Vector__XXX
 SG_ BMU_Temperature_C14_11 : 40|8@1+ (1,0) [0|0] "" Vector__XXX
 SG_ BMU_Temperature_Age_C14 : 48|16@1+ (1,0) [0|0] "" Vector__XXX

BO_ 2418312418 BMU_TransmitTemperature_N_14_P_2: 8 Vector__XXX
 SG_ BMU_Temperature_C14_12 : 0|8@1+ (1,0) [0|0] "" Vector__XXX
 SG_ BMU_Temperature_C14_13 : 8|8@1+ (1,0) [0|0] "" Vector__XXX
 SG_ BMU_Temperature_C14_14 : 16|8@1+ (1,0) [0|0] "" Vector__XXX
 SG_ BMU_Temperature_C14_15 : 24|8@1+ (1,0) [0|0] "" Vector__XXX
 SG_ BMU_Temperature_Age_C14 : 48|16@1+ (1,0) [0|0] "" Vector__XXX

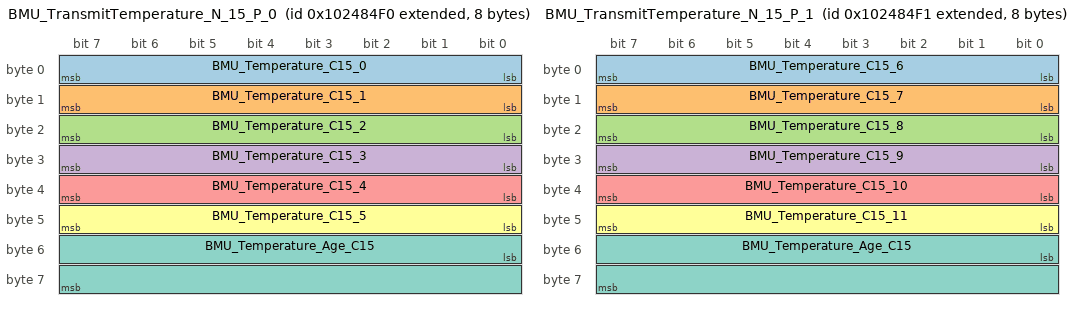
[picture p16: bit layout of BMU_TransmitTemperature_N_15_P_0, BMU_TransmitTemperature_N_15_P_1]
BO_ 2418312432 BMU_TransmitTemperature_N_15_P_0: 8 Vector__XXX
 SG_ BMU_Temperature_C15_0 : 0|8@1+ (1,0) [0|0] "" Vector__XXX
 SG_ BMU_Temperature_C15_1 : 8|8@1+ (1,0) [0|0] "" Vector__XXX
 SG_ BMU_Temperature_C15_2 : 16|8@1+ (1,0) [0|0] "" Vector__XXX
 SG_ BMU_Temperature_C15_3 : 24|8@1+ (1,0) [0|0] "" Vector__XXX
 SG_ BMU_Temperature_C15_4 : 32|8@1+ (1,0) [0|0] "" Vector__XXX
 SG_ BMU_Temperature_C15_5 : 40|8@1+ (1,0) [0|0] "" Vector__XXX
 SG_ BMU_Temperature_Age_C15 : 48|16@1+ (1,0) [0|0] "" Vector__XXX

BO_ 2418312433 BMU_TransmitTemperature_N_15_P_1: 8 Vector__XXX
 SG_ BMU_Temperature_C15_6 : 0|8@1+ (1,0) [0|0] "" Vector__XXX
 SG_ BMU_Temperature_C15_7 : 8|8@1+ (1,0) [0|0] "" Vector__XXX
 SG_ BMU_Temperature_C15_8 : 16|8@1+ (1,0) [0|0] "" Vector__XXX
 SG_ BMU_Temperature_C15_9 : 24|8@1+ (1,0) [0|0] "" Vector__XXX
 SG_ BMU_Temperature_C15_10 : 32|8@1+ (1,0) [0|0] "" Vector__XXX
 SG_ BMU_Temperature_C15_11 : 40|8@1+ (1,0) [0|0] "" Vector__XXX
 SG_ BMU_Temperature_Age_C15 : 48|16@1+ (1,0) [0|0] "" Vector__XXX

BO_ 2418312434 BMU_TransmitTemperature_N_15_P_2: 8 Vector__XXX
 SG_ BMU_Temperature_C15_12 : 0|8@1+ (1,0) [0|0] "" Vector__XXX
 SG_ BMU_Temperature_C15_13 : 8|8@1+ (1,0) [0|0] "" Vector__XXX
 SG_ BMU_Temperature_C15_14 : 16|8@1+ (1,0) [0|0] "" Vector__XXX
 SG_ BMU_Temperature_C15_15 : 24|8@1+ (1,0) [0|0] "" Vector__XXX
 SG_ BMU_Temperature_Age_C15 : 48|16@1+ (1,0) [0|0] "" Vector__XXX

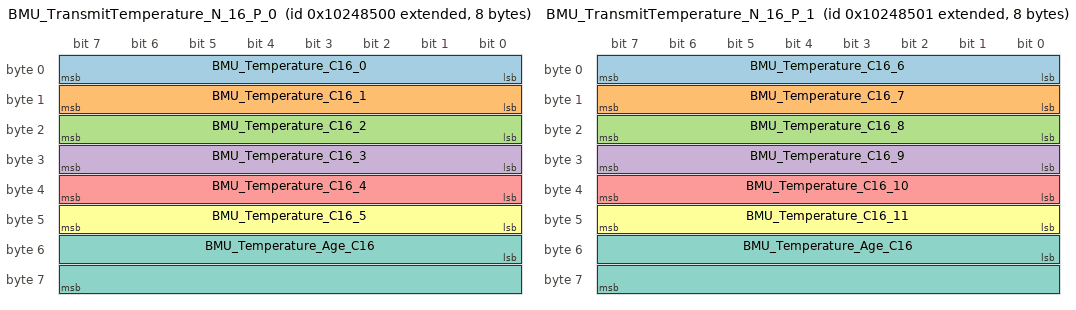
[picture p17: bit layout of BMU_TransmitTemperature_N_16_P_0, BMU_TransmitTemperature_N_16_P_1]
BO_ 2418312448 BMU_TransmitTemperature_N_16_P_0: 8 Vector__XXX
 SG_ BMU_Temperature_C16_0 : 0|8@1+ (1,0) [0|0] "" Vector__XXX
 SG_ BMU_Temperature_C16_1 : 8|8@1+ (1,0) [0|0] "" Vector__XXX
 SG_ BMU_Temperature_C16_2 : 16|8@1+ (1,0) [0|0] "" Vector__XXX
 SG_ BMU_Temperature_C16_3 : 24|8@1+ (1,0) [0|0] "" Vector__XXX
 SG_ BMU_Temperature_C16_4 : 32|8@1+ (1,0) [0|0] "" Vector__XXX
 SG_ BMU_Temperature_C16_5 : 40|8@1+ (1,0) [0|0] "" Vector__XXX
 SG_ BMU_Temperature_Age_C16 : 48|16@1+ (1,0) [0|0] "" Vector__XXX

BO_ 2418312449 BMU_TransmitTemperature_N_16_P_1: 8 Vector__XXX
 SG_ BMU_Temperature_C16_6 : 0|8@1+ (1,0) [0|0] "" Vector__XXX
 SG_ BMU_Temperature_C16_7 : 8|8@1+ (1,0) [0|0] "" Vector__XXX
 SG_ BMU_Temperature_C16_8 : 16|8@1+ (1,0) [0|0] "" Vector__XXX
 SG_ BMU_Temperature_C16_9 : 24|8@1+ (1,0) [0|0] "" Vector__XXX
 SG_ BMU_Temperature_C16_10 : 32|8@1+ (1,0) [0|0] "" Vector__XXX
 SG_ BMU_Temperature_C16_11 : 40|8@1+ (1,0) [0|0] "" Vector__XXX
 SG_ BMU_Temperature_Age_C16 : 48|16@1+ (1,0) [0|0] "" Vector__XXX

BO_ 2418312450 BMU_TransmitTemperature_N_16_P_2: 8 Vector__XXX
 SG_ BMU_Temperature_C16_12 : 0|8@1+ (1,0) [0|0] "" Vector__XXX
 SG_ BMU_Temperature_C16_13 : 8|8@1+ (1,0) [0|0] "" Vector__XXX
 SG_ BMU_Temperature_C16_14 : 16|8@1+ (1,0) [0|0] "" Vector__XXX
 SG_ BMU_Temperature_C16_15 : 24|8@1+ (1,0) [0|0] "" Vector__XXX
 SG_ BMU_Temperature_Age_C16 : 48|16@1+ (1,0) [0|0] "" Vector__XXX

BO_ 2418312464 BMU_TransmitTemperature_N_17_P_0: 8 Vector__XXX
 SG_ BMU_Temperature_C17_0 : 0|8@1+ (1,0) [0|0] "" Vector__XXX
 SG_ BMU_Temperature_C17_1 : 8|8@1+ (1,0) [0|0] "" Vector__XXX
 SG_ BMU_Temperature_C17_2 : 16|8@1+ (1,0) [0|0] "" Vector__XXX
 SG_ BMU_Temperature_C17_3 : 24|8@1+ (1,0) [0|0] "" Vector__XXX
 SG_ BMU_Temperature_C17_4 : 32|8@1+ (1,0) [0|0] "" Vector__XXX
 SG_ BMU_Temperature_C17_5 : 40|8@1+ (1,0) [0|0] "" Vector__XXX
 SG_ BMU_Temperature_Age_C17 : 48|16@1+ (1,0) [0|0] "" Vector__XXX

BO_ 2418312465 BMU_TransmitTemperature_N_17_P_1: 8 Vector__XXX
 SG_ BMU_Temperature_C17_6 : 0|8@1+ (1,0) [0|0] "" Vector__XXX
 SG_ BMU_Temperature_C17_7 : 8|8@1+ (1,0) [0|0] "" Vector__XXX
 SG_ BMU_Temperature_C17_8 : 16|8@1+ (1,0) [0|0] "" Vector__XXX
 SG_ BMU_Temperature_C17_9 : 24|8@1+ (1,0) [0|0] "" Vector__XXX
 SG_ BMU_Temperature_C17_10 : 32|8@1+ (1,0) [0|0] "" Vector__XXX
 SG_ BMU_Temperature_C17_11 : 40|8@1+ (1,0) [0|0] "" Vector__XXX
 SG_ BMU_Temperature_Age_C17 : 48|16@1+ (1,0) [0|0] "" Vector__XXX

BO_ 2418312466 BMU_TransmitTemperature_N_17_P_2: 8 Vector__XXX
 SG_ BMU_Temperature_C17_12 : 0|8@1+ (1,0) [0|0] "" Vector__XXX
 SG_ BMU_Temperature_C17_13 : 8|8@1+ (1,0) [0|0] "" Vector__XXX
 SG_ BMU_Temperature_C17_14 : 16|8@1+ (1,0) [0|0] "" Vector__XXX
 SG_ BMU_Temperature_C17_15 : 24|8@1+ (1,0) [0|0] "" Vector__XXX
 SG_ BMU_Temperature_Age_C17 : 48|16@1+ (1,0) [0|0] "" Vector__XXX

BO_ 2418312480 BMU_TransmitTemperature_N_18_P_0: 8 Vector__XXX
 SG_ BMU_Temperature_C18_0 : 0|8@1+ (1,0) [0|0] "" Vector__XXX
 SG_ BMU_Temperature_C18_1 : 8|8@1+ (1,0) [0|0] "" Vector__XXX
 SG_ BMU_Temperature_C18_2 : 16|8@1+ (1,0) [0|0] "" Vector__XXX
 SG_ BMU_Temperature_C18_3 : 24|8@1+ (1,0) [0|0] "" Vector__XXX
 SG_ BMU_Temperature_C18_4 : 32|8@1+ (1,0) [0|0] "" Vector__XXX
 SG_ BMU_Temperature_C18_5 : 40|8@1+ (1,0) [0|0] "" Vector__XXX
 SG_ BMU_Temperature_Age_C18 : 48|16@1+ (1,0) [0|0] "" Vector__XXX

BO_ 2418312481 BMU_TransmitTemperature_N_18_P_1: 8 Vector__XXX
 SG_ BMU_Temperature_C18_6 : 0|8@1+ (1,0) [0|0] "" Vector__XXX
 SG_ BMU_Temperature_C18_7 : 8|8@1+ (1,0) [0|0] "" Vector__XXX
 SG_ BMU_Temperature_C18_8 : 16|8@1+ (1,0) [0|0] "" Vector__XXX
 SG_ BMU_Temperature_C18_9 : 24|8@1+ (1,0) [0|0] "" Vector__XXX
 SG_ BMU_Temperature_C18_10 : 32|8@1+ (1,0) [0|0] "" Vector__XXX
 SG_ BMU_Temperature_C18_11 : 40|8@1+ (1,0) [0|0] "" Vector__XXX
 SG_ BMU_Temperature_Age_C18 : 48|16@1+ (1,0) [0|0] "" Vector__XXX

BO_ 2418312482 BMU_TransmitTemperature_N_18_P_2: 8 Vector__XXX
 SG_ BMU_Temperature_C18_12 : 0|8@1+ (1,0) [0|0] "" Vector__XXX
 SG_ BMU_Temperature_C18_13 : 8|8@1+ (1,0) [0|0] "" Vector__XXX
 SG_ BMU_Temperature_C18_14 : 16|8@1+ (1,0) [0|0] "" Vector__XXX
 SG_ BMU_Temperature_C18_15 : 24|8@1+ (1,0) [0|0] "" Vector__XXX
 SG_ BMU_Temperature_Age_C18 : 48|16@1+ (1,0) [0|0] "" Vector__XXX

BO_ 2418312496 BMU_TransmitTemperature_N_19_P_0: 8 Vector__XXX
 SG_ BMU_Temperature_C19_0 : 0|8@1+ (1,0) [0|0] "" Vector__XXX
 SG_ BMU_Temperature_C19_1 : 8|8@1+ (1,0) [0|0] "" Vector__XXX
 SG_ BMU_Temperature_C19_2 : 16|8@1+ (1,0) [0|0] "" Vector__XXX
 SG_ BMU_Temperature_C19_3 : 24|8@1+ (1,0) [0|0] "" Vector__XXX
 SG_ BMU_Temperature_C19_4 : 32|8@1+ (1,0) [0|0] "" Vector__XXX
 SG_ BMU_Temperature_C19_5 : 40|8@1+ (1,0) [0|0] "" Vector__XXX
 SG_ BMU_Temperature_Age_C19 : 48|16@1+ (1,0) [0|0] "" Vector__XXX

BO_ 2418312497 BMU_TransmitTemperature_N_19_P_1: 8 Vector__XXX
 SG_ BMU_Temperature_C19_6 : 0|8@1+ (1,0) [0|0] "" Vector__XXX
 SG_ BMU_Temperature_C19_7 : 8|8@1+ (1,0) [0|0] "" Vector__XXX
 SG_ BMU_Temperature_C19_8 : 16|8@1+ (1,0) [0|0] "" Vector__XXX
 SG_ BMU_Temperature_C19_9 : 24|8@1+ (1,0) [0|0] "" Vector__XXX
 SG_ BMU_Temperature_C19_10 : 32|8@1+ (1,0) [0|0] "" Vector__XXX
 SG_ BMU_Temperature_C19_11 : 40|8@1+ (1,0) [0|0] "" Vector__XXX
 SG_ BMU_Temperature_Age_C19 : 48|16@1+ (1,0) [0|0] "" Vector__XXX

BO_ 2418312498 BMU_TransmitTemperature_N_19_P_2: 8 Vector__XXX
 SG_ BMU_Temperature_C19_12 : 0|8@1+ (1,0) [0|0] "" Vector__XXX
 SG_ BMU_Temperature_C19_13 : 8|8@1+ (1,0) [0|0] "" Vector__XXX
 SG_ BMU_Temperature_C19_14 : 16|8@1+ (1,0) [0|0] "" Vector__XXX
 SG_ BMU_Temperature_C19_15 : 24|8@1+ (1,0) [0|0] "" Vector__XXX
 SG_ BMU_Temperature_Age_C19 : 48|16@1+ (1,0) [0|0] "" Vector__XXX

BO_ 2418313216 BMU_TransmitBalancing_N_0: 8 Vector__XXX
 SG_ BMU_BalanceState_C0 : 0|16@1+ (1,0) [0|0] "" Vector__XXX
 SG_ BMU_DieTemp_C0 : 16|8@1+ (1,0) [0|0] "" Vector__XXX

BO_ 2418313232 BMU_TransmitBalancing_N_1: 8 Vector__XXX
 SG_ BMU_BalanceState_C1 : 0|16@1+ (1,0) [0|0] "" Vector__XXX
 SG_ BMU_DieTemp_C1 : 16|8@1+ (1,0) [0|0] "" Vector__XXX

BO_ 2418313248 BMU_TransmitBalancing_N_2: 8 Vector__XXX
 SG_ BMU_BalanceState_C2 : 0|16@1+ (1,0) [0|0] "" Vector__XXX
 SG_ BMU_DieTemp_C2 : 16|8@1+ (1,0) [0|0] "" Vector__XXX

BO_ 2418313264 BMU_TransmitBalancing_N_3: 8 Vector__XXX
 SG_ BMU_BalanceState_C3 : 0|16@1+ (1,0) [0|0] "" Vector__XXX
 SG_ BMU_DieTemp_C3 : 16|8@1+ (1,0) [0|0] "" Vector__XXX

BO_ 2418313280 BMU_TransmitBalancing_N_4: 8 Vector__XXX
 SG_ BMU_BalanceState_C4 : 0|16@1+ (1,0) [0|0] "" Vector__XXX
 SG_ BMU_DieTemp_C4 : 16|8@1+ (1,0) [0|0] "" Vector__XXX

BO_ 2418313296 BMU_TransmitBalancing_N_5: 8 Vector__XXX
 SG_ BMU_BalanceState_C5 : 0|16@1+ (1,0) [0|0] "" Vector__XXX
 SG_ BMU_DieTemp_C5 : 16|8@1+ (1,0) [0|0] "" Vector__XXX

BO_ 2418313312 BMU_TransmitBalancing_N_6: 8 Vector__XXX
 SG_ BMU_BalanceState_C6 : 0|16@1+ (1,0) [0|0] "" Vector__XXX
 SG_ BMU_DieTemp_C6 : 16|8@1+ (1,0) [0|0] "" Vector__XXX

BO_ 2418313328 BMU_TransmitBalancing_N_7: 8 Vector__XXX
 SG_ BMU_BalanceState_C7 : 0|16@1+ (1,0) [0|0] "" Vector__XXX
 SG_ BMU_DieTemp_C7 : 16|8@1+ (1,0) [0|0] "" Vector__XXX

BO_ 2418313344 BMU_TransmitBalancing_N_8: 8 Vector__XXX
 SG_ BMU_BalanceState_C8 : 0|16@1+ (1,0) [0|0] "" Vector__XXX
 SG_ BMU_DieTemp_C8 : 16|8@1+ (1,0) [0|0] "" Vector__XXX

BO_ 2418313360 BMU_TransmitBalancing_N_9: 8 Vector__XXX
 SG_ BMU_BalanceState_C9 : 0|16@1+ (1,0) [0|0] "" Vector__XXX
 SG_ BMU_DieTemp_C9 : 16|8@1+ (1,0) [0|0] "" Vector__XXX

BO_ 2418313376 BMU_TransmitBalancing_N_10: 8 Vector__XXX
 SG_ BMU_BalanceState_C10 : 0|16@1+ (1,0) [0|0] "" Vector__XXX
 SG_ BMU_DieTemp_C10 : 16|8@1+ (1,0) [0|0] "" Vector__XXX

BO_ 2418313392 BMU_TransmitBalancing_N_11: 8 Vector__XXX
 SG_ BMU_BalanceState_C11 : 0|16@1+ (1,0) [0|0] "" Vector__XXX
 SG_ BMU_DieTemp_C11 : 16|8@1+ (1,0) [0|0] "" Vector__XXX

BO_ 2418313408 BMU_TransmitBalancing_N_12: 8 Vector__XXX
 SG_ BMU_BalanceState_C12 : 0|16@1+ (1,0) [0|0] "" Vector__XXX
 SG_ BMU_DieTemp_C12 : 16|8@1+ (1,0) [0|0] "" Vector__XXX

BO_ 2418313424 BMU_TransmitBalancing_N_13: 8 Vector__XXX
 SG_ BMU_BalanceState_C13 : 0|16@1+ (1,0) [0|0] "" Vector__XXX
 SG_ BMU_DieTemp_C13 : 16|8@1+ (1,0) [0|0] "" Vector__XXX

BO_ 2418313440 BMU_TransmitBalancing_N_14: 8 Vector__XXX
 SG_ BMU_BalanceState_C14 : 0|16@1+ (1,0) [0|0] "" Vector__XXX
 SG_ BMU_DieTemp_C14 : 16|8@1+ (1,0) [0|0] "" Vector__XXX

BO_ 2418313456 BMU_TransmitBalancing_N_15: 8 Vector__XXX
 SG_ BMU_BalanceState_C15 : 0|16@1+ (1,0) [0|0] "" Vector__XXX
 SG_ BMU_DieTemp_C15 : 16|8@1+ (1,0) [0|0] "" Vector__XXX

BO_ 2418313472 BMU_TransmitBalancing_N_16: 8 Vector__XXX
 SG_ BMU_BalanceState_C16 : 0|16@1+ (1,0) [0|0] "" Vector__XXX
 SG_ BMU_DieTemp_C16 : 16|8@1+ (1,0) [0|0] "" Vector__XXX

BO_ 2418313488 BMU_TransmitBalancing_N_17: 8 Vector__XXX
 SG_ BMU_BalanceState_C17 : 0|16@1+ (1,0) [0|0] "" Vector__XXX
 SG_ BMU_DieTemp_C17 : 16|8@1+ (1,0) [0|0] "" Vector__XXX

BO_ 2418313504 BMU_TransmitBalancing_N_18: 8 Vector__XXX
 SG_ BMU_BalanceState_C18 : 0|16@1+ (1,0) [0|0] "" Vector__XXX
 SG_ BMU_DieTemp_C18 : 16|8@1+ (1,0) [0|0] "" Vector__XXX

BO_ 2418313520 BMU_TransmitBalancing_N_19: 8 Vector__XXX
 SG_ BMU_BalanceState_C19 : 0|16@1+ (1,0) [0|0] "" Vector__XXX
 SG_ BMU_DieTemp_C19 : 16|8@1+ (1,0) [0|0] "" Vector__XXX

BO_ 2147485952 VESC_0_CAN_PACKET_STATUS: 8 Vector__XXX
 SG_ VESC_0_ERPM : 7|32@0+ (1,0) [0|0] "RPM" Vector__XXX
 SG_ VESC_0_Current : 39|16@0+ (0.1,0) [0|0] "A" Vector__XXX
 SG_ VESC_0_Duty_Cycle : 55|16@0+ (0.001,0) [0|0] "%" Vector__XXX

BO_ 2147485953 VESC_1_CAN_PACKET_STATUS: 8 Vector__XXX
 SG_ VESC_1_ERPM : 7|32@0+ (1,0) [0|0] "RPM" Vector__XXX
 SG_ VESC_1_Current : 39|16@0+ (0.1,0) [0|0] "A" Vector__XXX
 SG_ VESC_1_Duty_Cycle : 55|16@0+ (0.001,0) [0|0] "%" Vector__XXX

BO_ 2147485954 VESC_2_CAN_PACKET_STATUS: 8 Vector__XXX
 SG_ VESC_2_ERPM : 7|32@0+ (1,0) [0|0] "RPM" Vector__XXX
 SG_ VESC_2_Current : 39|16@0+ (0.1,0) [0|0] "A" Vector__XXX
 SG_ VESC_2_Duty_Cycle : 55|16@0+ (0.001,0) [0|0] "%" Vector__XXX

BO_ 2147485955 VESC_3_CAN_PACKET_STATUS: 8 Vector__XXX
 SG_ VESC_3_ERPM : 7|32@0+ (1,0) [0|0] "RPM" Vector__XXX
 SG_ VESC_3_Current : 39|16@0+ (0.1,0) [0|0] "A" Vector__XXX
 SG_ VESC_3_Duty_Cycle : 55|16@0+ (0.001,0) [0|0] "%" Vector__XXX

BO_ 2147487232 VESC_0_CAN_PACKET_STATUS_2: 8 Vector__XXX
 SG_ VESC_0_Amp_Hours : 7|32@0+ (0.0001,0) [0|0] "Ah" Vector__XXX
 SG_ VESC_0_Amp_Hours_Chg : 39|32@0+ (0.0001,0) [0|0] "Ah" Vector__XXX

BO_ 2147487233 VESC_1_CAN_PACKET_STATUS_2: 8 Vector__XXX
 SG_ VESC_1_Amp_Hours : 7|32@0+ (0.0001,0) [0|0] "Ah" Vector__XXX
 SG_ VESC_1_Amp_Hours_Chg : 39|32@0+ (0.0001,0) [0|0] "Ah" Vector__XXX

BO_ 2147487234 VESC_2_CAN_PACKET_STATUS_2: 8 Vector__XXX
 SG_ VESC_2_Amp_Hours : 7|32@0+ (0.0001,0) [0|0] "Ah" Vector__XXX
 SG_ VESC_2_Amp_Hours_Chg : 39|32@0+ (0.0001,0) [0|0] "Ah" Vector__XXX

BO_ 2147487235 VESC_3_CAN_PACKET_STATUS_2: 8 Vector__XXX
 SG_ VESC_3_Amp_Hours : 7|32@0+ (0.0001,0) [0|0] "Ah" Vector__XXX
 SG_ VESC_3_Amp_Hours_Chg : 39|32@0+ (0.0001,0) [0|0] "Ah" Vector__XXX

BO_ 2147487488 VESC_0_CAN_PACKET_STATUS_3: 8 Vector__XXX
 SG_ VESC_0_Watt_Hours : 7|32@0+ (0.0001,0) [0|0] "Wh" Vector__XXX
 SG_ VESC_0_Watt_Hours_Chg : 39|32@0+ (0.0001,0) [0|0] "Wh" Vector__XXX

BO_ 2147487489 VESC_1_CAN_PACKET_STATUS_3: 8 Vector__XXX
 SG_ VESC_1_Watt_Hours : 7|32@0+ (0.0001,0) [0|0] "Wh" Vector__XXX
 SG_ VESC_1_Watt_Hours_Chg : 39|32@0+ (0.0001,0) [0|0] "Wh" Vector__XXX

BO_ 2147487490 VESC_2_CAN_PACKET_STATUS_3: 8 Vector__XXX
 SG_ VESC_2_Watt_Hours : 7|32@0+ (0.0001,0) [0|0] "Wh" Vector__XXX
 SG_ VESC_2_Watt_Hours_Chg : 39|32@0+ (0.0001,0) [0|0] "Wh" Vector__XXX

BO_ 2147487491 VESC_3_CAN_PACKET_STATUS_3: 8 Vector__XXX
 SG_ VESC_3_Watt_Hours : 7|32@0+ (0.0001,0) [0|0] "Wh" Vector__XXX
 SG_ VESC_3_Watt_Hours_Chg : 39|32@0+ (0.0001,0) [0|0] "Wh" Vector__XXX

BO_ 2147487744 VESC_0_CAN_PACKET_STATUS_4: 8 Vector__XXX
 SG_ VESC_0_Temp_FET : 7|16@0+ (0.1,0) [0|0] "DegC" Vector__XXX
 SG_ VESC_0_Temp_Motor : 23|16@0+ (0.1,0) [0|0] "DegC" Vector__XXX
 SG_ VESC_0_Current_In : 39|16@0+ (0.1,0) [0|0] "A" Vector__XXX
 SG_ VESC_0_PID_Pos : 55|16@0+ (0.02,0) [0|0] "Deg" Vector__XXX

BO_ 2147487745 VESC_1_CAN_PACKET_STATUS_4: 8 Vector__XXX
 SG_ VESC_1_Temp_FET : 7|16@0+ (0.1,0) [0|0] "DegC" Vector__XXX
 SG_ VESC_1_Temp_Motor : 23|16@0+ (0.1,0) [0|0] "DegC" Vector__XXX
 SG_ VESC_1_Current_In : 39|16@0+ (0.1,0) [0|0] "A" Vector__XXX
 SG_ VESC_1_PID_Pos : 55|16@0+ (0.02,0) [0|0] "Deg" Vector__XXX

BO_ 2147487746 VESC_2_CAN_PACKET_STATUS_4: 8 Vector__XXX
 SG_ VESC_2_Temp_FET : 7|16@0+ (0.1,0) [0|0] "DegC" Vector__XXX
 SG_ VESC_2_Temp_Motor : 23|16@0+ (0.1,0) [0|0] "DegC" Vector__XXX
 SG_ VESC_2_Current_In : 39|16@0+ (0.1,0) [0|0] "A" Vector__XXX
 SG_ VESC_2_PID_Pos : 55|16@0+ (0.02,0) [0|0] "Deg" Vector__XXX

BO_ 2147487747 VESC_3_CAN_PACKET_STATUS_4: 8 Vector__XXX
 SG_ VESC_3_Temp_FET : 7|16@0+ (0.1,0) [0|0] "DegC" Vector__XXX
 SG_ VESC_3_Temp_Motor : 23|16@0+ (0.1,0) [0|0] "DegC" Vector__XXX
 SG_ VESC_3_Current_In : 39|16@0+ (0.1,0) [0|0] "A" Vector__XXX
 SG_ VESC_3_PID_Pos : 55|16@0+ (0.02,0) [0|0] "Deg" Vector__XXX

BO_ 2147490560 VESC_0_CAN_PACKET_STATUS_5: 8 Vector__XXX
 SG_ VESC_0_Tachometer : 7|32@0+ (0.1667,0) [0|0] "EREV" Vector__XXX
 SG_ VESC_0_Volts_In : 39|16@0+ (0.1,0) [0|0] "V" Vector__XXX

BO_ 2147490561 VESC_1_CAN_PACKET_STATUS_5: 8 Vector__XXX
 SG_ VESC_1_Tachometer : 7|32@0+ (0.1667,0) [0|0] "EREV" Vector__XXX
 SG_ VESC_1_Volts_In : 39|16@0+ (0.1,0) [0|0] "V" Vector__XXX

BO_ 2147490562 VESC_2_CAN_PACKET_STATUS_5: 8 Vector__XXX
 SG_ VESC_2_Tachometer : 7|32@0+ (0.1667,0) [0|0] "EREV" Vector__XXX
 SG_ VESC_2_Volts_In : 39|16@0+ (0.1,0) [0|0] "V" Vector__XXX

BO_ 2147490563 VESC_3_CAN_PACKET_STATUS_5: 8 Vector__XXX
 SG_ VESC_3_Tachometer : 7|32@0+ (0.1667,0) [0|0] "EREV" Vector__XXX
 SG_ VESC_3_Volts_In : 39|16@0+ (0.1,0) [0|0] "V" Vector__XXX

BO_ 2147491584 VESC_0_CAN_PACKET_SHUTDOWN: 0 Vector__XXX

BO_ 2147491585 VESC_1_CAN_PACKET_SHUTDOWN: 0 Vector__XXX

BO_ 2147491586 VESC_2_CAN_PACKET_SHUTDOWN: 0 Vector__XXX

BO_ 2147491587 VESC_3_CAN_PACKET_SHUTDOWN: 0 Vector__XXX

BO_ 544 SBG_ECAN_MSG_AUTO_SLIP_CURV: 7 Vector__XXX
 SG_ AUTO_STATUS : 48|8@1+ (1,0) [0|255] "" Vector__XXX
 SG_ CURVATURE_RADIUS : 32|16@1+ (0.01,0) [0|655.35] "m" Vector__XXX
 SG_ ANGLE_SLIP : 16|16@1- (0.0001,0) [-3.2768|3.2767] "rad" Vector__XXX
 SG_ ANGLE_TRACK : 0|16@1- (0.0001,0) [-3.2768|3.2767] "rad" Vector__XXX

BO_ 521 SBG_ECAN_MSG_EVENT_TIME_E: 8 Vector__XXX
 SG_ TIME_OFFSET_3 : 48|16@1+ (1,0) [0|65535] "µs" Vector__XXX
 SG_ TIME_OFFSET_2 : 32|16@1+ (1,0) [0|65535] "µs" Vector__XXX
 SG_ TIME_OFFSET_1 : 16|16@1+ (1,0) [0|65535] "µs" Vector__XXX
 SG_ TIME_OFFSET_0 : 0|16@1+ (1,0) [0|65535] "µs" Vector__XXX

BO_ 520 SBG_ECAN_MSG_EVENT_INFO_E: 8 Vector__XXX
 SG_ STATUS : 32|16@1+ (1,0) [0|65535] "" Vector__XXX
 SG_ TIME_STAMP : 0|32@1+ (1,0) [0|4294970000] "µs" Vector__XXX

BO_ 519 SBG_ECAN_MSG_EVENT_TIME_D: 8 Vector__XXX
 SG_ TIME_OFFSET_3 : 48|16@1+ (1,0) [0|65535] "µs" Vector__XXX
 SG_ TIME_OFFSET_2 : 32|16@1+ (1,0) [0|65535] "µs" Vector__XXX
 SG_ TIME_OFFSET_1 : 16|16@1+ (1,0) [0|65535] "µs" Vector__XXX
 SG_ TIME_OFFSET_0 : 0|16@1+ (1,0) [0|65535] "µs" Vector__XXX

BO_ 518 SBG_ECAN_MSG_EVENT_INFO_D: 8 Vector__XXX
 SG_ STATUS : 32|16@1+ (1,0) [0|65535] "" Vector__XXX
 SG_ TIME_STAMP : 0|32@1+ (1,0) [0|4294970000] "µs" Vector__XXX

BO_ 517 SBG_ECAN_MSG_EVENT_TIME_C: 8 Vector__XXX
 SG_ TIME_OFFSET_3 : 48|16@1+ (1,0) [0|65535] "µs" Vector__XXX
 SG_ TIME_OFFSET_2 : 32|16@1+ (1,0) [0|65535] "µs" Vector__XXX
 SG_ TIME_OFFSET_1 : 16|16@1+ (1,0) [0|65535] "µs" Vector__XXX
 SG_ TIME_OFFSET_0 : 0|16@1+ (1,0) [0|65535] "µs" Vector__XXX

BO_ 516 SBG_ECAN_MSG_EVENT_INFO_C: 8 Vector__XXX
 SG_ STATUS : 32|16@1+ (1,0) [0|65535] "" Vector__XXX
 SG_ TIME_STAMP : 0|32@1+ (1,0) [0|4294970000] "µs" Vector__XXX

BO_ 515 SBG_ECAN_MSG_EVENT_TIME_B: 8 Vector__XXX
 SG_ TIME_OFFSET_3 : 48|16@1+ (1,0) [0|65535] "µs" Vector__XXX
 SG_ TIME_OFFSET_2 : 32|16@1+ (1,0) [0|65535] "µs" Vector__XXX
 SG_ TIME_OFFSET_1 : 16|16@1+ (1,0) [0|65535] "µs" Vector__XXX
 SG_ TIME_OFFSET_0 : 0|16@1+ (1,0) [0|65535] "µs" Vector__XXX

BO_ 514 SBG_ECAN_MSG_EVENT_INFO_B: 8 Vector__XXX
 SG_ STATUS : 32|16@1+ (1,0) [0|65535] "" Vector__XXX
 SG_ TIME_STAMP : 0|32@1+ (1,0) [0|4294970000] "µs" Vector__XXX

BO_ 513 SBG_ECAN_MSG_EVENT_TIME_A: 8 Vector__XXX
 SG_ TIME_OFFSET_3 : 48|16@1+ (1,0) [0|65535] "µs" Vector__XXX
 SG_ TIME_OFFSET_2 : 32|16@1+ (1,0) [0|65535] "µs" Vector__XXX
 SG_ TIME_OFFSET_1 : 16|16@1+ (1,0) [0|65535] "µs" Vector__XXX
 SG_ TIME_OFFSET_0 : 0|16@1+ (1,0) [0|65535] "µs" Vector__XXX

BO_ 512 SBG_ECAN_MSG_EVENT_INFO_A: 8 Vector__XXX
 SG_ STATUS : 32|16@1+ (1,0) [0|65535] "" Vector__XXX
 SG_ TIME_STAMP : 0|32@1+ (1,0) [0|4294970000] "µs" Vector__XXX

BO_ 393 SBG_ECAN_MSG_GPS2_HDT: 8 Vector__XXX
 SG_ PITCH_ACC : 48|16@1+ (0.01,0) [0|655.35] "°" Vector__XXX
 SG_ PITCH : 32|16@1- (0.01,0) [-327.68|327.67] "°" Vector__XXX
 SG_ TRUE_HEADING_ACC : 16|16@1+ (0.01,0) [0|655.35] "°" Vector__XXX
 SG_ TRUE_HEADING : 0|16@1+ (0.01,0) [0|655.35] "°" Vector__XXX

BO_ 392 SBG_ECAN_MSG_GPS2_HDT_INFO: 6 Vector__XXX
 SG_ STATUS : 32|16@1+ (1,0) [0|65535] "" Vector__XXX
 SG_ TIME_STAMP : 0|32@1+ (1,0) [0|4294970000] "µs" Vector__XXX

BO_ 391 SBG_ECAN_MSG_GPS2_POS_ACC: 8 Vector__XXX
 SG_ BASE_STATION_ID : 48|16@1+ (1,0) [0|65535] "" Vector__XXX
 SG_ ALTITUDE_ACC : 32|16@1+ (0.01,0) [0|655.35] "m" Vector__XXX
 SG_ LONGITUDE_ACC : 16|16@1+ (0.01,0) [0|655.35] "m" Vector__XXX
 SG_ LATITUDE_ACC : 0|16@1+ (0.01,0) [0|655.35] "m" Vector__XXX

BO_ 390 SBG_ECAN_MSG_GPS2_POS_ALT: 8 Vector__XXX
 SG_ DIFF_CORR_AGE : 56|8@1+ (1,0) [0|255] "s" Vector__XXX
 SG_ NUM_SV : 48|8@1+ (1,0) [0|255] "" Vector__XXX
 SG_ UNDULATION : 32|16@1- (0.005,0) [-163.84|163.835] "m" Vector__XXX
 SG_ ALTITUDE : 0|32@1- (0.001,0) [-2147480|2147480] "m" Vector__XXX

BO_ 389 SBG_ECAN_MSG_GPS2_POS: 8 Vector__XXX
 SG_ LONGITUDE : 32|32@1- (1E-007,0) [-214.7483648|214.7483647] "°" Vector__XXX
 SG_ LATITUDE : 0|32@1- (1E-007,0) [-214.7483648|214.7483647] "°" Vector__XXX

BO_ 388 SBG_ECAN_MSG_GPS2_POS_INFO: 8 Vector__XXX
 SG_ STATUS : 32|32@1+ (1,0) [0|4294970000] "" Vector__XXX
 SG_ TIME_STAMP : 0|32@1+ (1,0) [0|4294970000] "µs" Vector__XXX

BO_ 387 SBG_ECAN_MSG_GPS2_VEL_COURSE: 4 Vector__XXX
 SG_ COURSE_ACC : 16|16@1+ (0.01,0) [0|655.35] "°" Vector__XXX
 SG_ COURSE : 0|16@1+ (0.01,0) [0|655.35] "°" Vector__XXX

BO_ 386 SBG_ECAN_MSG_GPS2_VEL_ACC: 6 Vector__XXX
 SG_ VELOCITY_ACC_D : 32|16@1- (0.01,0) [-327.68|327.67] "m.s-1" Vector__XXX
 SG_ VELOCITY_ACC_E : 16|16@1- (0.01,0) [-327.68|327.67] "m.s-1" Vector__XXX
 SG_ VELOCITY_ACC_N : 0|16@1- (0.01,0) [-327.68|327.67] "m.s-1" Vector__XXX

BO_ 385 SBG_ECAN_MSG_GPS2_VEL: 6 Vector__XXX
 SG_ VELOCITY_D : 32|16@1- (0.01,0) [-327.68|327.67] "m.s-1" Vector__XXX
 SG_ VELOCITY_E : 16|16@1- (0.01,0) [-327.68|327.67] "m.s-1" Vector__XXX
 SG_ VELOCITY_N : 0|16@1- (0.01,0) [-327.68|327.67] "m.s-1" Vector__XXX

BO_ 384 SBG_ECAN_MSG_GPS2_VEL_INFO: 8 Vector__XXX
 SG_ STATUS : 32|32@1+ (1,0) [0|4294970000] "" Vector__XXX
 SG_ TIME_STAMP : 0|32@1+ (1,0) [0|4294970000] "µs" Vector__XXX

BO_ 377 SBG_ECAN_MSG_GPS1_HDT: 8 Vector__XXX
 SG_ PITCH_ACC : 48|16@1+ (0.01,0) [0|655.35] "°" Vector__XXX
 SG_ PITCH : 32|16@1- (0.01,0) [-327.68|327.67] "°" Vector__XXX
 SG_ TRUE_HEADING_ACC : 16|16@1+ (0.01,0) [0|655.35] "°" Vector__XXX
 SG_ TRUE_HEADING : 0|16@1+ (0.01,0) [0|655.35] "°" Vector__XXX

BO_ 376 SBG_ECAN_MSG_GPS1_HDT_INFO: 6 Vector__XXX
 SG_ STATUS : 32|16@1+ (1,0) [0|65535] "" Vector__XXX
 SG_ TIME_STAMP : 0|32@1+ (1,0) [0|4294970000] "µs" Vector__XXX

BO_ 375 SBG_ECAN_MSG_GPS1_POS_ACC: 8 Vector__XXX
 SG_ BASE_STATION_ID : 48|16@1+ (1,0) [0|65535] "" Vector__XXX
 SG_ ALTITUDE_ACC : 32|16@1+ (0.01,0) [0|655.35] "m" Vector__XXX
 SG_ LONGITUDE_ACC : 16|16@1+ (0.01,0) [0|655.35] "m" Vector__XXX
 SG_ LATITUDE_ACC : 0|16@1+ (0.01,0) [0|655.35] "m" Vector__XXX

BO_ 374 SBG_ECAN_MSG_GPS1_POS_ALT: 8 Vector__XXX
 SG_ DIFF_CORR_AGE : 56|8@1+ (1,0) [0|255] "s" Vector__XXX
 SG_ NUM_SV : 48|8@1+ (1,0) [0|255] "" Vector__XXX
 SG_ UNDULATION : 32|16@1- (0.005,0) [-163.84|163.835] "m" Vector__XXX
 SG_ ALTITUDE : 0|32@1- (0.001,0) [-2147480|2147480] "m" Vector__XXX

BO_ 373 SBG_ECAN_MSG_GPS1_POS: 8 Vector__XXX
 SG_ LONGITUDE : 32|32@1- (1E-007,0) [-214.7483648|214.7483647] "°" Vector__XXX
 SG_ LATITUDE : 0|32@1- (1E-007,0) [-214.7483648|214.7483647] "°" Vector__XXX

BO_ 372 SBG_ECAN_MSG_GPS1_POS_INFO: 8 Vector__XXX
 SG_ STATUS : 32|32@1+ (1,0) [0|4294970000] "" Vector__XXX
 SG_ TIME_STAMP : 0|32@1+ (1,0) [0|4294970000] "µs" Vector__XXX

BO_ 371 SBG_ECAN_MSG_GPS1_VEL_COURSE: 4 Vector__XXX
 SG_ COURSE_ACC : 16|16@1+ (0.01,0) [0|655.35] "°" Vector__XXX
 SG_ COURSE : 0|16@1+ (0.01,0) [0|655.35] "°" Vector__XXX

BO_ 370 SBG_ECAN_MSG_GPS1_VEL_ACC: 6 Vector__XXX
 SG_ VELOCITY_ACC_D : 32|16@1- (0.01,0) [-327.68|327.67] "m.s-1" Vector__XXX
 SG_ VELOCITY_ACC_E : 16|16@1- (0.01,0) [-327.68|327.67] "m.s-1" Vector__XXX
 SG_ VELOCITY_ACC_N : 0|16@1- (0.01,0) [-327.68|327.67] "m.s-1" Vector__XXX

BO_ 369 SBG_ECAN_MSG_GPS1_VEL: 6 Vector__XXX
 SG_ VELOCITY_D : 32|16@1- (0.01,0) [-327.68|327.67] "m.s-1" Vector__XXX
 SG_ VELOCITY_E : 16|16@1- (0.01,0) [-327.68|327.67] "m.s-1" Vector__XXX
 SG_ VELOCITY_N : 0|16@1- (0.01,0) [-327.68|327.67] "m.s-1" Vector__XXX

BO_ 368 SBG_ECAN_MSG_GPS1_VEL_INFO: 8 Vector__XXX
 SG_ STATUS : 32|32@1+ (1,0) [0|4294970000] "" Vector__XXX
 SG_ TIME_STAMP : 0|32@1+ (1,0) [0|4294970000] "µs" Vector__XXX

BO_ 359 SBG_ECAN_MSG_DEPTH_ALTITUDE: 8 Vector__XXX
 SG_ DEPTH : 32|32@1- (0.001,0) [-2147480|2147480] "m" Vector__XXX
 SG_ PRESSURE_ABS : 0|32@1+ (0.1,0) [0|429497000] "Pa" Vector__XXX

BO_ 358 SBG_ECAN_MSG_DEPTH_INFO: 5 Vector__XXX
 SG_ DEPTH_STATUS : 32|8@1+ (1,0) [0|255] "" Vector__XXX
 SG_ TIME_STAMP : 0|32@1+ (1,0) [0|4294970000] "us" Vector__XXX

BO_ 356 SBG_ECAN_MSG_AIR_DATA_AIRSPEED: 6 Vector__XXX
 SG_ AIRSPEED : 32|16@1- (0.01,0) [-327.68|327.67] "m.s-1" Vector__XXX
 SG_ PRESSURE_DIFF : 0|32@1- (0.001,0) [-2147483.648|2147483.647] "Pa" Vector__XXX

BO_ 355 SBG_ECAN_MSG_AIR_DATA_ALTITUDE: 8 Vector__XXX
 SG_ ALTITUDE : 32|32@1- (0.001,0) [-2147483.648|2147483.647] "m" Vector__XXX
 SG_ PRESSURE_ABS : 0|32@1+ (0.001,0) [0|4294967.295] "Pa" Vector__XXX

BO_ 354 SBG_ECAN_MSG_AIR_DATA_INFO: 7 Vector__XXX
 SG_ AIR_TEMPERATURE : 40|16@1- (0.01,0) [-327.68|327.67] "°C" Vector__XXX
 SG_ AIR_DATA_STATUS : 32|8@1+ (1,0) [0|255] "" Vector__XXX
 SG_ TIME_STAMP : 0|32@1+ (1,0) [0|4294970000] "us" Vector__XXX

BO_ 353 SBG_ECAN_MSG_ODO_VEL: 2 Vector__XXX
 SG_ VELOCITY : 0|16@1- (0.01,0) [-327.68|327.67] "m.s-1" Vector__XXX

BO_ 352 SBG_ECAN_MSG_ODO_INFO: 6 Vector__XXX
 SG_ ODO_STATUS : 32|16@1+ (1,0) [0|65535] "" Vector__XXX
 SG_ TIME_STAMP : 0|32@1+ (1,0) [0|4294970000] "µs" Vector__XXX

BO_ 338 SBG_ECAN_MSG_MAG_2: 6 Vector__XXX
 SG_ ACCEL_Z : 32|16@1- (0.01,0) [-327.68|327.67] "m.s-2" Vector__XXX
 SG_ ACCEL_Y : 16|16@1- (0.01,0) [-327.68|327.67] "m.s-2" Vector__XXX
 SG_ ACCEL_X : 0|16@1- (0.01,0) [-327.68|327.67] "m.s-2" Vector__XXX

BO_ 337 SBG_ECAN_MSG_MAG_1: 6 Vector__XXX
 SG_ MAG_Z : 32|16@1- (0.001,0) [-32.768|32.767] "a.u." Vector__XXX
 SG_ MAG_Y : 16|16@1- (0.001,0) [-32.768|32.767] "a.u." Vector__XXX
 SG_ MAG_X : 0|16@1- (0.001,0) [-32.768|32.767] "a.u." Vector__XXX

BO_ 336 SBG_ECAN_MSG_MAG_0: 6 Vector__XXX
 SG_ STATUS : 32|16@1+ (1,0) [0|65535] "" Vector__XXX
 SG_ TIME_STAMP : 0|32@1+ (1,0) [0|4294970000] "µs" Vector__XXX

BO_ 333 SBG_ECAN_MSG_SHIP_MOTION_HP_2: 6 Vector__XXX
 SG_ VEL_Z : 32|16@1- (0.01,0) [-327.68|327.67] "m.s-1" Vector__XXX
 SG_ VEL_Y : 16|16@1- (0.01,0) [-327.68|327.67] "m.s-1" Vector__XXX
 SG_ VEL_X : 0|16@1- (0.01,0) [-327.68|327.67] "m.s-1" Vector__XXX

BO_ 332 SBG_ECAN_MSG_SHIP_MOTION_HP_1: 6 Vector__XXX
 SG_ ACCEL_Z : 32|16@1- (0.01,0) [-327.68|327.67] "m.s-2" Vector__XXX
 SG_ ACCEL_Y : 16|16@1- (0.01,0) [-327.68|327.67] "m.s-2" Vector__XXX
 SG_ ACCEL_X : 0|16@1- (0.01,0) [-327.68|327.67] "m.s-2" Vector__XXX

BO_ 331 SBG_ECAN_MSG_SHIP_MOTION_HP_0: 6 Vector__XXX
 SG_ HEAVE : 32|16@1- (0.001,0) [-32.768|32.767] "m" Vector__XXX
 SG_ SWAY : 16|16@1- (0.001,0) [-32.768|32.767] "m" Vector__XXX
 SG_ SURGE : 0|16@1- (0.001,0) [-32.768|32.767] "m" Vector__XXX

BO_ 330 SBG_ECAN_MSG_SHIP_MOTION_HP_INFO: 8 Vector__XXX
 SG_ STATUS : 48|16@1+ (1,0) [0|65535] "" Vector__XXX
 SG_ PERIOD : 32|16@1+ (0.01,0) [0|655.35] "s" Vector__XXX
 SG_ TIME_STAMP : 0|32@1+ (1,0) [0|4294970000] "µs" Vector__XXX

BO_ 329 SBG_ECAN_MSG_SHIP_MOTION_2: 6 Vector__XXX
 SG_ VEL_Z : 32|16@1- (0.01,0) [-327.68|327.67] "m.s-1" Vector__XXX
 SG_ VEL_Y : 16|16@1- (0.01,0) [-327.68|327.67] "m.s-1" Vector__XXX
 SG_ VEL_X : 0|16@1- (0.01,0) [-327.68|327.67] "m.s-1" Vector__XXX

BO_ 325 SBG_ECAN_MSG_SHIP_MOTION_1: 6 Vector__XXX
 SG_ ACCEL_Z : 32|16@1- (0.01,0) [-327.68|327.67] "m.s-2" Vector__XXX
 SG_ ACCEL_Y : 16|16@1- (0.01,0) [-327.68|327.67] "m.s-2" Vector__XXX
 SG_ ACCEL_X : 0|16@1- (0.01,0) [-327.68|327.67] "m.s-2" Vector__XXX

BO_ 321 SBG_ECAN_MSG_SHIP_MOTION_0: 6 Vector__XXX
 SG_ HEAVE : 32|16@1- (0.001,0) [-32.768|32.767] "m" Vector__XXX
 SG_ SWAY : 16|16@1- (0.001,0) [-32.768|32.767] "m" Vector__XXX
 SG_ SURGE : 0|16@1- (0.001,0) [-32.768|32.767] "m" Vector__XXX

BO_ 320 SBG_ECAN_MSG_SHIP_MOTION_INFO: 8 Vector__XXX
 SG_ STATUS : 48|16@1+ (1,0) [0|65535] "" Vector__XXX
 SG_ PERIOD : 32|16@1+ (0.01,0) [0|655.35] "s" Vector__XXX
 SG_ TIME_STAMP : 0|32@1+ (1,0) [0|4294970000] "µs" Vector__XXX

BO_ 313 SBG_ECAN_MSG_EKF_VEL_BODY: 6 Vector__XXX
 SG_ VELOCITY_Z : 32|16@1- (0.01,0) [-327.68|327.67] "m.s-1" Vector__XXX
 SG_ VELOCITY_Y : 16|16@1- (0.01,0) [-327.68|327.67] "m.s-1" Vector__XXX
 SG_ VELOCITY_X : 0|16@1- (0.01,0) [-327.68|327.67] "m.s-1" Vector__XXX

BO_ 312 SBG_ECAN_MSG_EKF_VEL_NED_ACC: 6 Vector__XXX
 SG_ VELOCITY_ACC_D : 32|16@1- (0.01,0) [-327.68|327.67] "m.s-1" Vector__XXX
 SG_ VELOCITY_ACC_E : 16|16@1- (0.01,0) [-327.68|327.67] "m.s-1" Vector__XXX
 SG_ VELOCITY_ACC_N : 0|16@1- (0.01,0) [-327.68|327.67] "m.s-1" Vector__XXX

BO_ 311 SBG_ECAN_MSG_EKF_VEL_NED: 6 Vector__XXX
 SG_ VELOCITY_D : 32|16@1- (0.01,0) [-327.68|327.67] "m.s-1" Vector__XXX
 SG_ VELOCITY_E : 16|16@1- (0.01,0) [-327.68|327.67] "m.s-1" Vector__XXX
 SG_ VELOCITY_N : 0|16@1- (0.01,0) [-327.68|327.67] "m.s-1" Vector__XXX

BO_ 310 SBG_ECAN_MSG_EKF_POS_ACC: 6 Vector__XXX
 SG_ ALTITUDE_ACC : 32|16@1+ (0.01,0) [0|655.35] "m" Vector__XXX
 SG_ LONGITUDE_ACC : 16|16@1+ (0.01,0) [0|655.35] "m" Vector__XXX
 SG_ LATITUDE_ACC : 0|16@1+ (0.01,0) [0|655.35] "m" Vector__XXX

BO_ 309 SBG_ECAN_MSG_EKF_ALTITUDE: 6 Vector__XXX
 SG_ UNDULATION : 32|16@1- (0.005,0) [-163.84|163.835] "m" Vector__XXX
 SG_ ALTITUDE : 0|32@1- (0.001,0) [-2147480|2147480] "m" Vector__XXX

BO_ 308 SBG_ECAN_MSG_EKF_POS: 8 Vector__XXX
 SG_ LONGITUDE : 32|32@1- (1E-007,0) [-214.7483648|214.7483647] "°" Vector__XXX
 SG_ LATITUDE : 0|32@1- (1E-007,0) [-214.7483648|214.7483647] "°" Vector__XXX

BO_ 307 SBG_ECAN_MSG_EKF_ORIENTATION_ACC: 6 Vector__XXX
 SG_ YAW_ACC : 32|16@1+ (0.0001,0) [0|6.5535] "rad" Vector__XXX
 SG_ PITCH_ACC : 16|16@1+ (0.0001,0) [0|6.5535] "rad" Vector__XXX
 SG_ ROLL_ACC : 0|16@1+ (0.0001,0) [0|6.5535] "rad" Vector__XXX

BO_ 306 SBG_ECAN_MSG_EKF_EULER: 6 Vector__XXX
 SG_ YAW : 32|16@1- (0.0001,0) [-3.2768|3.2767] "rad" Vector__XXX
 SG_ PITCH : 16|16@1- (0.0001,0) [-3.2768|3.2767] "rad" Vector__XXX
 SG_ ROLL : 0|16@1- (0.0001,0) [-3.2768|3.2767] "rad" Vector__XXX

BO_ 305 SBG_ECAN_MSG_EKF_QUAT: 8 Vector__XXX
 SG_ Q3 : 48|16@1- (3.05185094759972E-005,0) [-1|1] "" Vector__XXX
 SG_ Q2 : 32|16@1- (3.05185094759972E-005,0) [-1|1] "" Vector__XXX
 SG_ Q1 : 16|16@1- (3.05185094759972E-005,0) [-1|1] "" Vector__XXX
 SG_ Q0 : 0|16@1- (3.05185094759972E-005,0) [-1|1] "" Vector__XXX

BO_ 304 SBG_ECAN_MSG_EKF_INFO: 4 Vector__XXX
 SG_ TIME_STAMP : 0|32@1+ (1,0) [0|4294970000] "µs" Vector__XXX

BO_ 292 SBG_ECAN_MSG_IMU_DELTA_ANGLE: 6 Vector__XXX
 SG_ DELTA_ANGLE_Z : 32|16@1- (0.001,0) [-32.768|32.767] "rad.s-1" Vector__XXX
 SG_ DELTA_ANGLE_Y : 16|16@1- (0.001,0) [-32.768|32.767] "rad.s-1" Vector__XXX
 SG_ DELTA_ANGLE_X : 0|16@1- (0.001,0) [-32.768|32.767] "rad.s-1" Vector__XXX

BO_ 291 SBG_ECAN_MSG_IMU_DELTA_VEL: 6 Vector__XXX
 SG_ DELTA_VEL_Z : 32|16@1- (0.01,0) [-327.68|327.67] "m.s-2" Vector__XXX
 SG_ DELTA_VEL_Y : 16|16@1- (0.01,0) [-327.68|327.67] "m.s-2" Vector__XXX
 SG_ DELTA_VEL_X : 0|16@1- (0.01,0) [-327.68|327.67] "m.s-2" Vector__XXX

BO_ 290 SBG_ECAN_MSG_IMU_GYRO: 6 Vector__XXX
 SG_ GYRO_Z : 32|16@1- (0.001,0) [-32.768|32.767] "rad.s-1" Vector__XXX
 SG_ GYRO_Y : 16|16@1- (0.001,0) [-32.768|32.767] "rad.s-1" Vector__XXX
 SG_ GYRO_X : 0|16@1- (0.001,0) [-32.768|32.767] "rad.s-1" Vector__XXX

BO_ 289 SBG_ECAN_MSG_IMU_ACCEL: 6 Vector__XXX
 SG_ ACCEL_Z : 32|16@1- (0.01,0) [-327.68|327.67] "m.s-2" Vector__XXX
 SG_ ACCEL_Y : 16|16@1- (0.01,0) [-327.68|327.67] "m.s-2" Vector__XXX
 SG_ ACCEL_X : 0|16@1- (0.01,0) [-327.68|327.67] "m.s-2" Vector__XXX

BO_ 288 SBG_ECAN_MSG_IMU_INFO: 8 Vector__XXX
 SG_ TEMPERATURE : 48|16@1- (0.01,0) [-327.68|327.67] "°C" Vector__XXX
 SG_ STATUS : 32|16@1+ (1,0) [0|65535] "" Vector__XXX
 SG_ TIME_STAMP : 0|32@1+ (1,0) [0|4294970000] "µs" Vector__XXX

BO_ 273 SBG_ECAN_MSG_UTC_1: 8 Vector__XXX
 SG_ MICRO_SEC : 48|16@1+ (100,0) [0|6553500] "us" Vector__XXX
 SG_ SEC : 40|8@1+ (1,0) [0|255] "s" Vector__XXX
 SG_ MIN : 32|8@1+ (1,0) [0|255] "min" Vector__XXX
 SG_ HOUR : 24|8@1+ (1,0) [0|255] "h" Vector__XXX
 SG_ DAY : 16|8@1+ (1,0) [0|255] "d" Vector__XXX
 SG_ MONTH : 8|8@1+ (1,0) [0|255] "month" Vector__XXX
 SG_ YEAR : 0|8@1+ (1,2000) [2000|2255] "year" Vector__XXX

BO_ 272 SBG_ECAN_MSG_UTC_0: 8 Vector__XXX
 SG_ GPS_TOW : 32|32@1+ (1,0) [0|4294970000] "ms" Vector__XXX
 SG_ TIME_STAMP : 0|32@1+ (1,0) [0|4294970000] "µs" Vector__XXX

BO_ 258 SBG_ECAN_MSG_STATUS_03: 6 Vector__XXX
 SG_ HEAVE_STATUS : 32|16@1+ (1,0) [0|65535] "" Vector__XXX
 SG_ SOLUTION : 0|32@1+ (1,0) [0|4294970000] "" Vector__XXX

BO_ 257 SBG_ECAN_MSG_STATUS_02: 8 Vector__XXX
 SG_ AIDING : 32|32@1+ (1,0) [0|4294970000] "" Vector__XXX
 SG_ COM : 0|32@1+ (1,0) [0|4294970000] "" Vector__XXX

BO_ 256 SBG_ECAN_MSG_STATUS_01: 8 Vector__XXX
 SG_ CLOCK : 48|16@1+ (1,0) [0|65535] "" Vector__XXX
 SG_ GENERAL : 32|16@1+ (1,0) [0|65535] "" Vector__XXX
 SG_ TIME_STAMP : 0|32@1+ (1,0) [0|4294970000] "µs" Vector__XXX

BO_ 2165338473 Sevcon_1_HC1: 8 Vector__XXX
 SG_ Sevcon_1_TorqueDemand : 0|16@1- (1,0) [0|0] "Nm" Vector__XXX
 SG_ Sevcon_1_ControlWord : 16|16@1+ (1,0) [0|0] "" Vector__XXX
 SG_ Sevcon_1_TorqueLimit : 32|16@1- (1,0) [0|0] "Nm" Vector__XXX

BO_ 2165404009 Sevcon_1_HC2: 8 Vector__XXX
 SG_ Sevcon_1_RegenTorqueLimit : 0|16@1- (1,0) [0|0] "Nm" Vector__XXX
 SG_ Sevcon_1_FwdSpeedLimit : 16|16@1+ (1,0) [0|0] "RPM" Vector__XXX
 SG_ Sevcon_1_RevSpeedLimit : 32|16@1- (1,0) [0|0] "RPM" Vector__XXX

BO_ 2165469545 Sevcon_1_HC3: 8 Vector__XXX
 SG_ Sevcon_1_DischargeLimit : 0|16@1- (1,0) [0|0] "A" Vector__XXX
 SG_ Sevcon_1_ChargeLimit : 16|16@1+ (1,0) [0|0] "A" Vector__XXX
 SG_ Sevcon_1_TargetCapVoltage : 32|16@1- (1,0) [0|0] "V" Vector__XXX

BO_ 2165338729 Sevcon_2_HC1: 8 Vector__XXX
 SG_ Sevcon_2_TorqueDemand : 0|16@1- (1,0) [0|0] "Nm" Vector__XXX
 SG_ Sevcon_2_ControlWord : 16|16@1+ (1,0) [0|0] "" Vector__XXX
 SG_ Sevcon_2_TorqueLimit : 32|16@1- (1,0) [0|0] "Nm" Vector__XXX

BO_ 2165404265 Sevcon_2_HC2: 8 Vector__XXX
 SG_ Sevcon_2_RegenTorqueLimit : 0|16@1- (1,0) [0|0] "Nm" Vector__XXX
 SG_ Sevcon_2_FwdSpeedLimit : 16|16@1+ (1,0) [0|0] "RPM" Vector__XXX
 SG_ Sevcon_2_RevSpeedLimit : 32|16@1- (1,0) [0|0] "RPM" Vector__XXX

BO_ 2165469801 Sevcon_2_HC3: 8 Vector__XXX
 SG_ Sevcon_2_DischargeLimit : 0|16@1- (1,0) [0|0] "A" Vector__XXX
 SG_ Sevcon_2_ChargeLimit : 16|16@1+ (1,0) [0|0] "A" Vector__XXX
 SG_ Sevcon_2_TargetCapVoltage : 32|16@1- (1,0) [0|0] "V" Vector__XXX

BO_ 2568552305 Sevcon_1_HS1: 8 Vector__XXX
 SG_ Sevcon_1_OutputTorque : 0|16@1- (0.0625,0) [0|0] "Nm" Vector__XXX
 SG_ Sevcon_1_Speed : 16|16@1- (1,0) [0|0] "RPM" Vector__XXX
 SG_ Sevcon_1_BatteryCurrent : 32|16@1- (1,0) [0|0] "A" Vector__XXX

BO_ 2568617841 Sevcon_1_HS2: 8 Vector__XXX
 SG_ Sevcon_1_AvailFwdTorque : 0|16@1- (0.0625,0) [0|0] "Nm" Vector__XXX
 SG_ Sevcon_1_AvailRevTorque : 16|16@1- (0.0625,0) [0|0] "Nm" Vector__XXX
 SG_ Sevcon_1_StatusWord : 32|16@1- (1,0) [0|0] "" Vector__XXX

BO_ 2568683377 Sevcon_1_HS3: 8 Vector__XXX
 SG_ Sevcon_1_HeatSinkTemp : 0|16@1- (1,0) [0|0] "degC" Vector__XXX
 SG_ Sevcon_1_RemainingTemp : 16|16@1- (1,0) [0|0] "degC" Vector__XXX
 SG_ Sevcon_1_CapVoltage : 32|16@1- (0.0625,0) [0|0] "V" Vector__XXX

BO_ 2568748913 Sevcon_1_HS4: 8 Vector__XXX
 SG_ Sevcon_1_FaultCode : 0|16@1+ (1,0) [0|0] "" Vector__XXX
 SG_ Sevcon_1_DebugBytes : 16|32@1+ (1,0) [0|0] "" Vector__XXX

BO_ 2568814449 Sevcon_1_HS5: 8 Vector__XXX
 SG_ Sevcon_1_EncoderAngle : 0|32@1- (1.525E-005,0) [0|0] "" Vector__XXX

BO_ 2568552306 Sevcon_2_HS1: 8 Vector__XXX
 SG_ Sevcon_2_OutputTorque : 0|16@1- (0.0625,0) [0|0] "Nm" Vector__XXX
 SG_ Sevcon_2_Speed : 16|16@1- (1,0) [0|0] "RPM" Vector__XXX
 SG_ Sevcon_2_BatteryCurrent : 32|16@1- (1,0) [0|0] "A" Vector__XXX

BO_ 2568617842 Sevcon_2_HS2: 8 Vector__XXX
 SG_ Sevcon_2_AvailFwdTorque : 0|16@1- (0.0625,0) [0|0] "Nm" Vector__XXX
 SG_ Sevcon_2_AvailRevTorque : 16|16@1- (0.0625,0) [0|0] "Nm" Vector__XXX
 SG_ Sevcon_2_StatusWord : 32|16@1- (1,0) [0|0] "" Vector__XXX

BO_ 2568683378 Sevcon_2_HS3: 8 Vector__XXX
 SG_ Sevcon_2_HeatSinkTemp : 0|16@1- (1,0) [0|0] "degC" Vector__XXX
 SG_ Sevcon_2_RemainingTemp : 16|16@1- (1,0) [0|0] "degC" Vector__XXX
 SG_ Sevcon_2_CapVoltage : 32|16@1- (0.0625,0) [0|0] "V" Vector__XXX

BO_ 2568748914 Sevcon_2_HS4: 8 Vector__XXX
 SG_ Sevcon_2_FaultCode : 0|16@1+ (1,0) [0|0] "" Vector__XXX
 SG_ Sevcon_2_DebugBytes : 16|32@1+ (1,0) [0|0] "" Vector__XXX

BO_ 2568814450 Sevcon_2_HS5: 8 Vector__XXX
 SG_ Sevcon_2_EncoderAngle : 0|32@1+ (1.525E-005,0) [0|0] "" Vector__XXX

BO_ 2569600881 Sevcon_1_HD1: 8 Vector__XXX
 SG_ Sevcon_1_IdActual : 0|16@1- (0.0625,0) [0|0] "A" Vector__XXX
 SG_ Sevcon_1_IqActual : 16|16@1- (0.0625,0) [0|0] "A" Vector__XXX
 SG_ Sevcon_1_IdRef : 32|16@1- (0.0625,0) [0|0] "A" Vector__XXX
 SG_ Sevcon_1_IqRef : 48|16@1- (0.0625,0) [0|0] "A" Vector__XXX

BO_ 2569666417 Sevcon_1_HD2: 8 Vector__XXX
 SG_ Sevcon_1_Ud : 0|16@1- (0.0625,0) [0|0] "V" Vector__XXX
 SG_ Sevcon_1_Uq : 16|16@1- (0.0625,0) [0|0] "V" Vector__XXX
 SG_ Sevcon_1_ModIndex : 32|16@1+ (0.0030517578125,0) [0|0] "%" Vector__XXX
 SG_ Sevcon_1_TargetTorque : 48|16@1- (0.0625,0) [0|0] "Nm" Vector__XXX

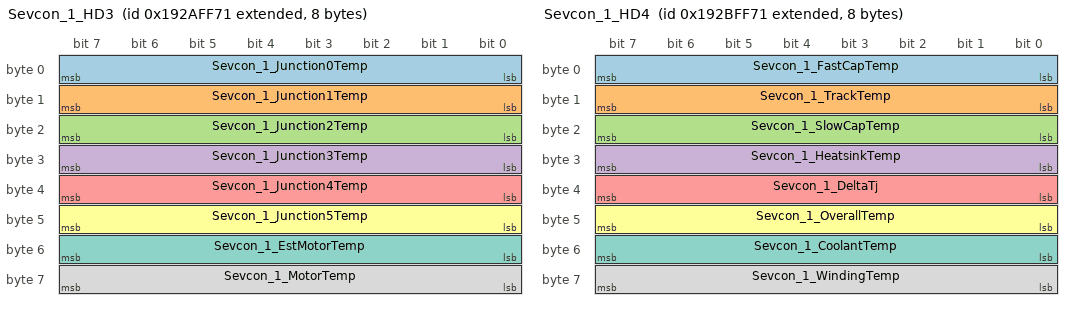
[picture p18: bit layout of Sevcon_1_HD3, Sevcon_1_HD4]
BO_ 2569731953 Sevcon_1_HD3: 8 Vector__XXX
 SG_ Sevcon_1_Junction0Temp : 0|8@1+ (1,0) [0|0] "degC" Vector__XXX
 SG_ Sevcon_1_Junction1Temp : 8|8@1+ (1,0) [0|0] "degC" Vector__XXX
 SG_ Sevcon_1_Junction2Temp : 16|8@1+ (1,0) [0|0] "degC" Vector__XXX
 SG_ Sevcon_1_Junction3Temp : 24|8@1+ (1,0) [0|0] "degC" Vector__XXX
 SG_ Sevcon_1_Junction4Temp : 32|8@1+ (1,0) [0|0] "degC" Vector__XXX
 SG_ Sevcon_1_Junction5Temp : 40|8@1+ (1,0) [0|0] "degC" Vector__XXX
 SG_ Sevcon_1_EstMotorTemp : 48|8@1+ (1,0) [0|0] "degC" Vector__XXX
 SG_ Sevcon_1_MotorTemp : 56|8@1+ (1,0) [0|0] "degC" Vector__XXX

BO_ 2569797489 Sevcon_1_HD4: 8 Vector__XXX
 SG_ Sevcon_1_FastCapTemp : 0|8@1+ (1,0) [0|0] "" Vector__XXX
 SG_ Sevcon_1_TrackTemp : 8|8@1+ (1,0) [0|0] "degC" Vector__XXX
 SG_ Sevcon_1_SlowCapTemp : 16|8@1+ (1,0) [0|0] "degC" Vector__XXX
 SG_ Sevcon_1_HeatsinkTemp : 24|8@1+ (1,0) [0|0] "degC" Vector__XXX
 SG_ Sevcon_1_DeltaTj : 32|8@1+ (1,0) [0|0] "degC" Vector__XXX
 SG_ Sevcon_1_OverallTemp : 40|8@1+ (1,0) [0|0] "degC" Vector__XXX
 SG_ Sevcon_1_CoolantTemp : 48|8@1+ (1,0) [0|0] "degC" Vector__XXX
 SG_ Sevcon_1_WindingTemp : 56|8@1+ (1,0) [0|0] "degC" Vector__XXX

BO_ 2569863025 Sevcon_1_HD5: 8 Vector__XXX
 SG_ Sevcon_1_MaxFlux : 0|16@1- (1,0) [0|0] "A" Vector__XXX
 SG_ Sevcon_1_IvLim : 16|16@1- (1,0) [0|0] "A" Vector__XXX
 SG_ Sevcon_1_IqMax : 32|16@1- (1,0) [0|0] "A" Vector__XXX
 SG_ Sevcon_1_Ls : 48|16@1+ (0.05960464498,0) [0|0] "uH" Vector__XXX

BO_ 2569600882 Sevcon_2_HD1: 8 Vector__XXX
 SG_ Sevcon_2_IdActual : 0|16@1- (0.0625,0) [0|0] "A" Vector__XXX
 SG_ Sevcon_2_IqActual : 16|16@1- (0.0625,0) [0|0] "A" Vector__XXX
 SG_ Sevcon_2_IdRef : 32|16@1- (0.0625,0) [0|0] "A" Vector__XXX
 SG_ Sevcon_2_IqRef : 48|16@1- (0.0625,0) [0|0] "A" Vector__XXX

BO_ 2569666418 Sevcon_2_HD2: 8 Vector__XXX
 SG_ Sevcon_2_Ud : 0|16@1- (0.0625,0) [0|0] "V" Vector__XXX
 SG_ Sevcon_2_Uq : 16|16@1- (0.0625,0) [0|0] "V" Vector__XXX
 SG_ Sevcon_2_ModIndex : 32|16@1+ (0.0030517578125,0) [0|0] "%" Vector__XXX
 SG_ Sevcon_2_TargetTorque : 48|16@1- (0.0625,0) [0|0] "Nm" Vector__XXX

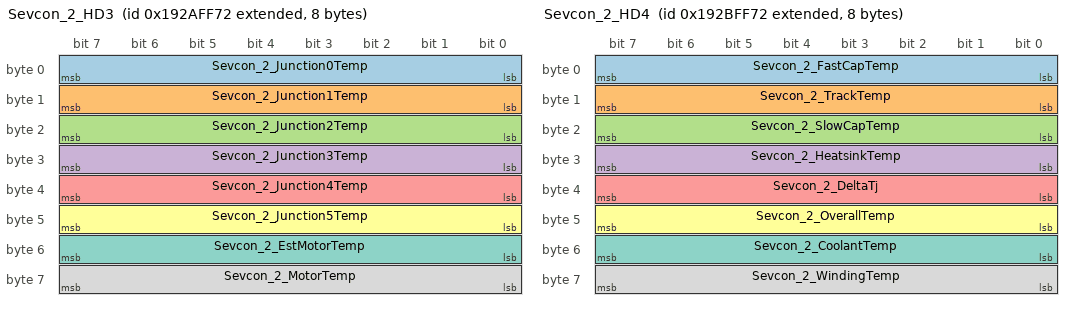
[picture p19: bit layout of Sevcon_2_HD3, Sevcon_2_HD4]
BO_ 2569731954 Sevcon_2_HD3: 8 Vector__XXX
 SG_ Sevcon_2_Junction0Temp : 0|8@1+ (1,0) [0|0] "degC" Vector__XXX
 SG_ Sevcon_2_Junction1Temp : 8|8@1+ (1,0) [0|0] "degC" Vector__XXX
 SG_ Sevcon_2_Junction2Temp : 16|8@1+ (1,0) [0|0] "degC" Vector__XXX
 SG_ Sevcon_2_Junction3Temp : 24|8@1+ (1,0) [0|0] "degC" Vector__XXX
 SG_ Sevcon_2_Junction4Temp : 32|8@1+ (1,0) [0|0] "degC" Vector__XXX
 SG_ Sevcon_2_Junction5Temp : 40|8@1+ (1,0) [0|0] "degC" Vector__XXX
 SG_ Sevcon_2_EstMotorTemp : 48|8@1+ (1,0) [0|0] "degC" Vector__XXX
 SG_ Sevcon_2_MotorTemp : 56|8@1+ (1,0) [0|0] "degC" Vector__XXX

BO_ 2569797490 Sevcon_2_HD4: 8 Vector__XXX
 SG_ Sevcon_2_FastCapTemp : 0|8@1+ (1,0) [0|0] "" Vector__XXX
 SG_ Sevcon_2_TrackTemp : 8|8@1+ (1,0) [0|0] "degC" Vector__XXX
 SG_ Sevcon_2_SlowCapTemp : 16|8@1+ (1,0) [0|0] "degC" Vector__XXX
 SG_ Sevcon_2_HeatsinkTemp : 24|8@1+ (1,0) [0|0] "degC" Vector__XXX
 SG_ Sevcon_2_DeltaTj : 32|8@1+ (1,0) [0|0] "degC" Vector__XXX
 SG_ Sevcon_2_OverallTemp : 40|8@1+ (1,0) [0|0] "degC" Vector__XXX
 SG_ Sevcon_2_CoolantTemp : 48|8@1+ (1,0) [0|0] "degC" Vector__XXX
 SG_ Sevcon_2_WindingTemp : 56|8@1+ (1,0) [0|0] "degC" Vector__XXX

BO_ 2569863026 Sevcon_2_HD5: 8 Vector__XXX
 SG_ Sevcon_2_MaxFlux : 0|16@1- (1,0) [0|0] "A" Vector__XXX
 SG_ Sevcon_2_IvLim : 16|16@1- (1,0) [0|0] "A" Vector__XXX
 SG_ Sevcon_2_IqMax : 32|16@1- (1,0) [0|0] "A" Vector__XXX
 SG_ Sevcon_2_Ls : 48|16@1+ (0.05960464498,0) [0|0] "uH" Vector__XXX

BA_DEF_  "BusType" STRING ;
BA_DEF_DEF_  "BusType" "CAN";
